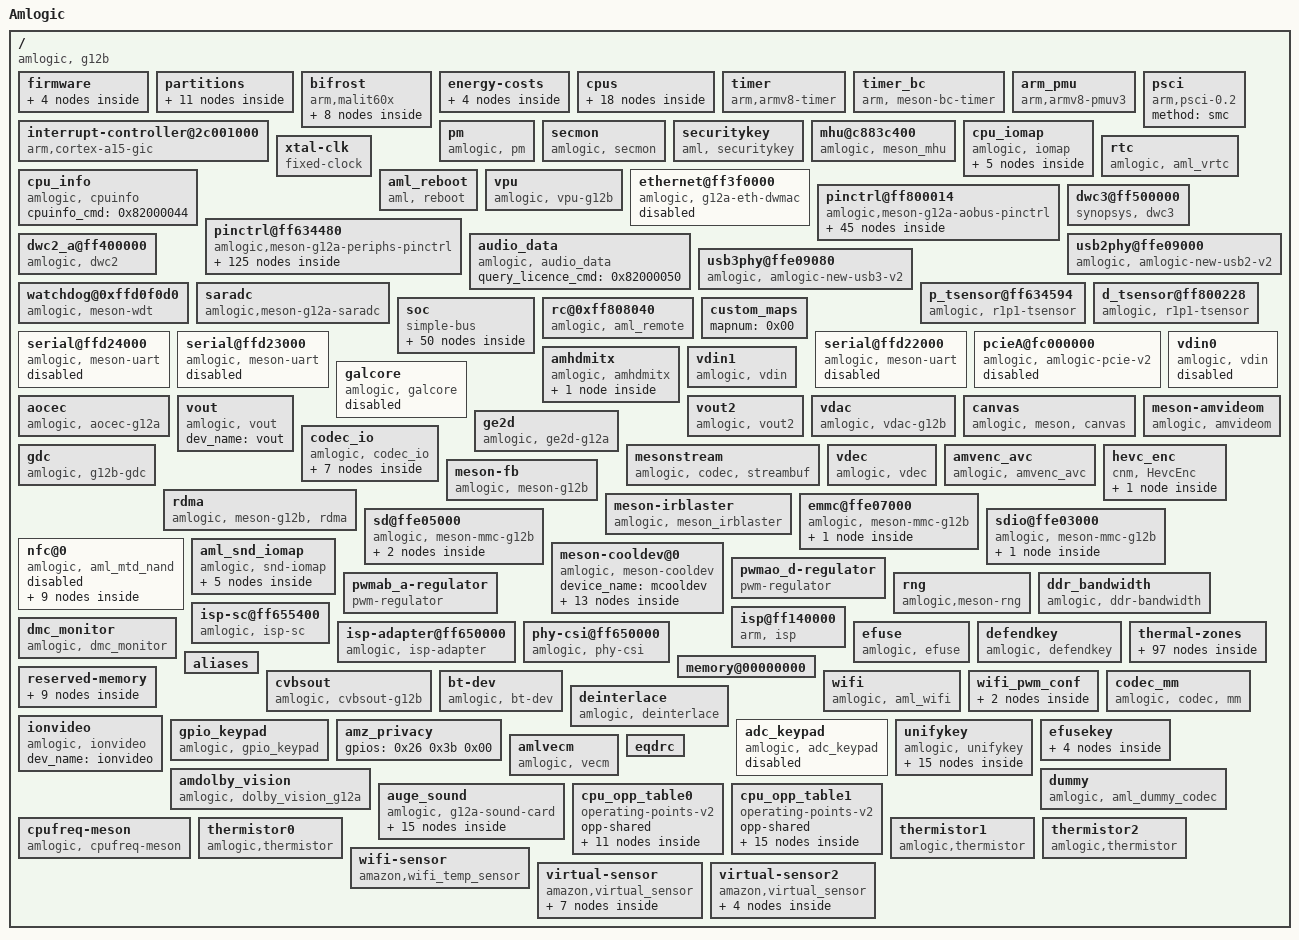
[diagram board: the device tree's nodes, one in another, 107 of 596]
/dts-v1/;

/ {
	model = "Amlogic";
	amlogic-dt-id = "g12brevb_raven_2g";
	compatible = "amlogic, g12b";
	interrupt-parent = <0x01>;
	#address-cells = <0x02>;
	#size-cells = <0x02>;

	firmware {

		android {
			compatible = "android,firmware";

			fstab {
				compatible = "android,fstab";

				vendor {
					compatible = "android,vendor";
					dev = "/dev/block/vendor";
					type = "ext4";
					mnt_flags = "ro";
					fsmgr_flags = "wait,verify";
				};

				odm {
					compatible = "android,odm";
					dev = "/dev/block/odm";
					type = "ext4";
					mnt_flags = "ro,barrier=1,inode_readahead_blks=8";
					fsmgr_flags = "wait";
				};
			};
		};
	};

	partitions {
		parts = <0x0b>;
		part-0 = <0x02>;
		part-1 = <0x03>;
		part-2 = <0x04>;
		part-3 = <0x05>;
		part-4 = <0x06>;
		part-5 = <0x07>;
		part-6 = <0x08>;
		part-7 = <0x09>;
		part-8 = <0x0a>;
		part-9 = <0x0b>;
		part-10 = <0x0c>;
		phandle = <0x99>;

		boot {
			pname = "boot";
			size = <0x00 0x1800000>;
			mask = <0x01>;
			phandle = <0x03>;
		};

		recovery {
			pname = "recovery";
			size = <0x00 0x1800000>;
			mask = <0x01>;
			phandle = <0x04>;
		};

		logo {
			pname = "logo";
			size = <0x00 0x400000>;
			mask = <0x01>;
			phandle = <0x05>;
		};

		tee {
			pname = "tee";
			size = <0x00 0x800000>;
			mask = <0x01>;
			phandle = <0x02>;
		};

		misc {
			pname = "misc";
			size = <0x00 0x100000>;
			mask = <0x02>;
			phandle = <0x06>;
		};

		vendor {
			pname = "vendor";
			size = <0x00 0x9600000>;
			mask = <0x01>;
			phandle = <0x07>;
		};

		odm {
			pname = "odm";
			size = <0x00 0x200000>;
			mask = <0x01>;
			phandle = <0x08>;
		};

		system {
			pname = "system";
			size = <0x00 0x64000000>;
			mask = <0x01>;
			phandle = <0x09>;
		};

		product {
			pname = "product";
			size = <0x00 0x200000>;
			mask = <0x01>;
			phandle = <0x0a>;
		};

		cache {
			pname = "cache";
			size = <0x00 0x20000000>;
			mask = <0x02>;
			phandle = <0x0b>;
		};

		data {
			pname = "data";
			size = <0xffffffff 0xffffffff>;
			mask = <0x04>;
			phandle = <0x0c>;
		};
	};

	bifrost {
		compatible = "arm,malit60x\0arm,malit6xx\0arm,mali-midgard";
		#cooling-cells = <0x02>;
		reg = <0x00 0xffe40000 0x00 0x4000 0x00 0xffd01000 0x00 0x1000 0x00 0xff800000 0x00 0x1000 0x00 0xff63c000 0x00 0x1000 0x00 0xffd01000 0x00 0x1000>;
		interrupt-parent = <0x01>;
		interrupts = <0x00 0xa0 0x04 0x00 0xa1 0x04 0x00 0xa2 0x04>;
		interrupt-names = "GPU\0MMU\0JOB";
		num_of_pp = <0x02>;
		sc_mpp = <0x01>;
		clocks = <0x0d 0x83 0x0d 0x07>;
		clock-names = "gpu_mux\0gp0_pll";
		tbl = <0x0e 0x0f 0x10 0x11 0x12 0x12>;
		system-coherency = <0x00>;
		phandle = <0x9a>;

		clk125_cfg {
			clk_freq = <0x7735940>;
			clk_parent = "fclk_div4";
			clkp_freq = <0x1dcd6500>;
			clk_reg = <0xa03>;
			voltage = <0x47e>;
			keep_count = <0x05>;
			threshold = <0x1e 0x78>;
			phandle = <0x9b>;
		};

		dvfs250_cfg {
			clk_freq = <0xee6b280>;
			clk_parent = "fclk_div4";
			clkp_freq = <0x1dcd6500>;
			clk_reg = <0xa01>;
			voltage = <0x47e>;
			keep_count = <0x05>;
			threshold = <0x50 0xaa>;
			phandle = <0x9c>;
		};

		dvfs285_cfg {
			clk_freq = <0x1107a76d>;
			clk_parent = "fclk_div7";
			clkp_freq = <0x1107a76d>;
			clk_reg = <0xe00>;
			voltage = <0x47e>;
			keep_count = <0x05>;
			threshold = <0x64 0xbe>;
			phandle = <0x0e>;
		};

		dvfs400_cfg {
			clk_freq = <0x17d78400>;
			clk_parent = "fclk_div5";
			clkp_freq = <0x17d78400>;
			clk_reg = <0xc00>;
			voltage = <0x47e>;
			keep_count = <0x05>;
			threshold = <0x98 0xcf>;
			phandle = <0x0f>;
		};

		dvfs500_cfg {
			clk_freq = <0x1dcd6500>;
			clk_parent = "fclk_div4";
			clkp_freq = <0x1dcd6500>;
			clk_reg = <0xa00>;
			voltage = <0x47e>;
			keep_count = <0x05>;
			threshold = <0xb4 0xdc>;
			phandle = <0x10>;
		};

		dvfs666_cfg {
			clk_freq = <0x27bc86aa>;
			clk_parent = "fclk_div3";
			clkp_freq = <0x27bc86aa>;
			clk_reg = <0x800>;
			voltage = <0x47e>;
			keep_count = <0x05>;
			threshold = <0xd2 0xec>;
			phandle = <0x11>;
		};

		dvfs800_cfg {
			clk_freq = <0x2faf0800>;
			clk_parent = "fclk_div2p5";
			clkp_freq = <0x2faf0800>;
			clk_reg = <0x600>;
			voltage = <0x47e>;
			keep_count = <0x05>;
			threshold = <0xe6 0xff>;
			phandle = <0x12>;
		};

		dvfs850_cfg {
			clk_freq = <0x326cef80>;
			clk_parent = "gp0_pll";
			clkp_freq = <0x326cef80>;
			clk_reg = <0x200>;
			voltage = <0x47e>;
			keep_count = <0x05>;
			threshold = <0xe6 0xff>;
			phandle = <0x9d>;
		};
	};

	energy-costs {

		core-cost0 {
			busy-cost-data = <0x36 0x11 0x87 0x6e 0x10e 0xca 0x168 0x108 0x21c 0x18c 0x288 0x1d6 0x2f3 0x22d 0x330 0x26c 0x364 0x2bb 0x398 0x2f7 0x3cc 0x333 0x406 0x377 0x440 0x3a9 0x46e 0x3d0 0x4a8 0x418>;
			idle-cost-data = <0x05 0x00 0x00>;
			phandle = <0x1d>;
		};

		core-cost1 {
			busy-cost-data = <0x21 0x04 0x53 0x17 0xa6 0x29 0xdd 0x36 0x14c 0x4e 0x18f 0x5c 0x1d1 0x74 0x1f7 0x87 0x217 0xa2 0x237 0xb8 0x257 0xe0 0x277 0x117>;
			idle-cost-data = <0x03 0x00 0x00>;
			phandle = <0x19>;
		};

		cluster-cost0 {
			busy-cost-data = <0x36 0x11 0x87 0x14 0x10e 0x19 0x168 0x1b 0x21c 0x23 0x288 0x28 0x2f3 0x31 0x330 0x39 0x364 0x36 0x398 0x40 0x3cc 0x4b 0x406 0x56 0x440 0x61 0x46e 0x6c 0x4a8 0x6e>;
			idle-cost-data = <0x0a 0x0a 0x00>;
			phandle = <0x1e>;
		};

		cluster-cost1 {
			busy-cost-data = <0x21 0x07 0x53 0x08 0xa6 0x09 0xdd 0x0a 0x14c 0x0d 0x18f 0x0f 0x1d1 0x13 0x1f7 0x17 0x217 0x1a 0x237 0x1f 0x257 0x24 0x277 0x2a>;
			idle-cost-data = <0x06 0x06 0x00>;
			phandle = <0x1a>;
		};
	};

	cpus {
		#address-cells = <0x02>;
		#size-cells = <0x00>;
		phandle = <0x9e>;

		cpu-map {

			cluster0 {
				phandle = <0x9f>;

				core0 {
					cpu = <0x13>;
				};

				core1 {
					cpu = <0x14>;
				};
			};

			cluster1 {
				phandle = <0xa0>;

				core0 {
					cpu = <0x15>;
				};

				core1 {
					cpu = <0x16>;
				};

				core2 {
					cpu = <0x17>;
				};

				core3 {
					cpu = <0x18>;
				};
			};
		};

		cpu@0 {
			device_type = "cpu";
			compatible = "arm,cortex-a53\0arm,armv8";
			reg = <0x00 0x00>;
			enable-method = "psci";
			sched-energy-costs = <0x19 0x1a>;
			clocks = <0x0d 0x17 0x0d 0x16 0x0d 0xee>;
			clock-names = "core_clk\0low_freq_clk_parent\0high_freq_clk_parent";
			operating-points-v2 = <0x1b>;
			cpu-supply = <0x1c>;
			voltage-tolerance = <0x00>;
			clock-latency = <0xc350>;
			phandle = <0x13>;
		};

		cpu@1 {
			device_type = "cpu";
			compatible = "arm,cortex-a53\0arm,armv8";
			reg = <0x00 0x01>;
			enable-method = "psci";
			sched-energy-costs = <0x19 0x1a>;
			clocks = <0x0d 0x17 0x0d 0x16 0x0d 0xee>;
			clock-names = "core_clk\0low_freq_clk_parent\0high_freq_clk_parent";
			operating-points-v2 = <0x1b>;
			cpu-supply = <0x1c>;
			voltage-tolerance = <0x00>;
			clock-latency = <0xc350>;
			phandle = <0x14>;
		};

		cpu@100 {
			device_type = "cpu";
			compatible = "arm,cortex-a73\0arm,armv8";
			reg = <0x00 0x100>;
			enable-method = "psci";
			sched-energy-costs = <0x1d 0x1e>;
			clocks = <0x0d 0xde 0x0d 0xdd 0x0d 0x00>;
			clock-names = "core_clk\0low_freq_clk_parent\0high_freq_clk_parent";
			operating-points-v2 = <0x1f>;
			cpu-supply = <0x20>;
			voltage-tolerance = <0x00>;
			clock-latency = <0xc350>;
			phandle = <0x15>;
		};

		cpu@101 {
			device_type = "cpu";
			compatible = "arm,cortex-a73\0arm,armv8";
			reg = <0x00 0x101>;
			enable-method = "psci";
			sched-energy-costs = <0x1d 0x1e>;
			clocks = <0x0d 0xde 0x0d 0xdd 0x0d 0x00>;
			clock-names = "core_clk\0low_freq_clk_parent\0high_freq_clk_parent";
			operating-points-v2 = <0x1f>;
			cpu-supply = <0x20>;
			voltage-tolerance = <0x00>;
			clock-latency = <0xc350>;
			phandle = <0x16>;
		};

		cpu@102 {
			device_type = "cpu";
			compatible = "arm,cortex-a73\0arm,armv8";
			reg = <0x00 0x102>;
			enable-method = "psci";
			sched-energy-costs = <0x1d 0x1e>;
			clocks = <0x0d 0xde 0x0d 0xdd 0x0d 0x00>;
			clock-names = "core_clk\0low_freq_clk_parent\0high_freq_clk_parent";
			operating-points-v2 = <0x1f>;
			cpu-supply = <0x20>;
			voltage-tolerance = <0x00>;
			clock-latency = <0xc350>;
			phandle = <0x17>;
		};

		cpu@103 {
			device_type = "cpu";
			compatible = "arm,cortex-a73\0arm,armv8";
			reg = <0x00 0x103>;
			enable-method = "psci";
			sched-energy-costs = <0x1d 0x1e>;
			clocks = <0x0d 0xde 0x0d 0xdd 0x0d 0x00>;
			clock-names = "core_clk\0low_freq_clk_parent\0high_freq_clk_parent";
			operating-points-v2 = <0x1f>;
			cpu-supply = <0x20>;
			voltage-tolerance = <0x00>;
			clock-latency = <0xc350>;
			phandle = <0x18>;
		};

		idle-states {
			entry-method = "arm,psci";

			cpu-sleep-0 {
				compatible = "arm,idle-state";
				arm,psci-suspend-param = <0x10000>;
				local-timer-stop;
				entry-latency-us = <0x1f40>;
				exit-latency-us = <0x1f40>;
				min-residency-us = <0x4e20>;
				phandle = <0xa1>;
			};

			cluster-sleep-0 {
				compatible = "arm,idle-state";
				arm,psci-suspend-param = <0x1010000>;
				local-timer-stop;
				entry-latency-us = <0x2328>;
				exit-latency-us = <0x2328>;
				min-residency-us = <0x61a8>;
				phandle = <0xa2>;
			};
		};
	};

	timer {
		compatible = "arm,armv8-timer";
		interrupts = <0x01 0x0d 0xff08 0x01 0x0e 0xff08 0x01 0x0b 0xff08 0x01 0x0a 0xff08>;
	};

	timer_bc {
		compatible = "arm, meson-bc-timer";
		reg = <0x00 0xffd0f190 0x00 0x04 0x00 0xffd0f194 0x00 0x04>;
		timer_name = "Meson TimerF";
		clockevent-rating = <0x12c>;
		clockevent-shift = <0x14>;
		clockevent-features = <0x23>;
		interrupts = <0x00 0x3c 0x01>;
		bit_enable = <0x10>;
		bit_mode = <0x0c>;
		bit_resolution = <0x00>;
	};

	arm_pmu {
		compatible = "arm,armv8-pmuv3";
		clusterb-enabled;
		interrupts = <0x00 0x89 0x04 0x00 0xab 0x04>;
		reg = <0x00 0xff634680 0x00 0x04 0x00 0xff6347c0 0x00 0x04>;
		cpumasks = <0x03 0x3c>;
		relax-timer-ns = <0x989680>;
		max-wait-cnt = <0x2710>;
	};

	interrupt-controller@2c001000 {
		compatible = "arm,cortex-a15-gic\0arm,cortex-a9-gic";
		#interrupt-cells = <0x03>;
		#address-cells = <0x00>;
		interrupt-controller;
		reg = <0x00 0xffc01000 0x00 0x1000 0x00 0xffc02000 0x00 0x100>;
		interrupts = <0x01 0x09 0xf04>;
		phandle = <0x01>;
	};

	psci {
		compatible = "arm,psci-0.2";
		method = "smc";
	};

	pm {
		compatible = "amlogic, pm";
		status = "okay";
		device_name = "aml_pm";
		reg = <0x00 0xff8000a8 0x00 0x04 0x00 0xff80023c 0x00 0x04>;
		phandle = <0xa3>;
	};

	secmon {
		compatible = "amlogic, secmon";
		memory-region = <0x21>;
		in_base_func = <0x82000020>;
		out_base_func = <0x82000021>;
		reserve_mem_size = <0x2300000>;
		clear_range = <0x5100000 0x1e00000>;
	};

	securitykey {
		compatible = "aml, securitykey";
		storage_query = <0x82000060>;
		storage_read = <0x82000061>;
		storage_write = <0x82000062>;
		storage_tell = <0x82000063>;
		storage_verify = <0x82000064>;
		storage_status = <0x82000065>;
		storage_list = <0x82000067>;
		storage_remove = <0x82000068>;
		storage_in_func = <0x82000023>;
		storage_out_func = <0x82000024>;
		storage_block_func = <0x82000025>;
		storage_size_func = <0x82000027>;
		storage_set_enctype = <0x8200006a>;
		storage_get_enctype = <0x8200006b>;
		storage_version = <0x8200006c>;
	};

	mhu@c883c400 {
		compatible = "amlogic, meson_mhu";
		reg = <0x00 0xff63c400 0x00 0x4c 0x00 0xfffe7000 0x00 0x800>;
		interrupts = <0x00 0xd1 0x01 0x00 0xd2 0x01>;
		#mbox-cells = <0x01>;
		mbox-names = "cpu_to_scp_low\0cpu_to_scp_high";
		mboxes = <0x22 0x00 0x22 0x01>;
		phandle = <0x22>;
	};

	cpu_iomap {
		compatible = "amlogic, iomap";
		#address-cells = <0x02>;
		#size-cells = <0x02>;
		ranges;

		io_cbus_base {
			reg = <0x00 0xffd00000 0x00 0x26000>;
		};

		io_apb_base {
			reg = <0x00 0xffe01000 0x00 0x7f000>;
		};

		io_aobus_base {
			reg = <0x00 0xff800000 0x00 0xb000>;
		};

		io_vapb_base {
			reg = <0x00 0xff900000 0x00 0x50000>;
		};

		io_hiu_base {
			reg = <0x00 0xff63c000 0x00 0x2000>;
		};
	};

	xtal-clk {
		compatible = "fixed-clock";
		clock-frequency = <0x16e3600>;
		clock-output-names = "xtal";
		#clock-cells = <0x00>;
		phandle = <0x27>;
	};

	rtc {
		compatible = "amlogic, aml_vrtc";
		alarm_reg_addr = <0xff8000a8>;
		timer_e_addr = <0xffd0f188>;
		init_date = "2019/01/01";
		status = "okay";
	};

	cpu_info {
		compatible = "amlogic, cpuinfo";
		status = "okay";
		cpuinfo_cmd = <0x82000044>;
	};

	aml_reboot {
		compatible = "aml, reboot";
		sys_reset = <0x84000009>;
		sys_poweroff = <0x84000008>;
	};

	vpu {
		compatible = "amlogic, vpu-g12b";
		dev_name = "vpu";
		status = "okay";
		clocks = <0x0d 0x95 0x0d 0x4c 0x0d 0x87 0x0d 0x8b 0x0d 0x8c>;
		clock-names = "vapb_clk\0vpu_intr_gate\0vpu_clk0\0vpu_clk1\0vpu_clk";
		clk_level = <0x07>;
	};

	ethernet@ff3f0000 {
		compatible = "amlogic, g12a-eth-dwmac\0snps,dwmac";
		reg = <0x00 0xff3f0000 0x00 0x10000 0x00 0xff634540 0x00 0x08 0x00 0xff64c000 0x00 0xa0>;
		reg-names = "eth_base\0eth_cfg\0eth_pll";
		interrupts = <0x00 0x08 0x01>;
		interrupt-names = "macirq";
		status = "disable";
		clocks = <0x0d 0x38>;
		clock-names = "ethclk81";
		pll_val = <0x9c0040a 0x927e0000 0xac5f49e5>;
		analog_val = <0x20200000 0xc000 0x23>;
		pinctrl-names = "external_eth_pins";
		pinctrl-0 = <0x23>;
		mc_val = <0x1621>;
		internal_phy = <0x00>;
		phandle = <0xa4>;
	};

	pinctrl@ff800014 {
		compatible = "amlogic,meson-g12a-aobus-pinctrl";
		#address-cells = <0x02>;
		#size-cells = <0x02>;
		ranges;
		phandle = <0xa5>;

		ao-bank@ff800014 {
			reg = <0x00 0xff800014 0x00 0x08 0x00 0xff800024 0x00 0x14 0x00 0xff80001c 0x00 0x08>;
			reg-names = "mux\0gpio\0drive-strength";
			gpio-controller;
			#gpio-cells = <0x02>;
			phandle = <0xa6>;
		};

		ao_uart {
			phandle = <0xa7>;

			mux {
				groups = "uart_ao_tx_a\0uart_ao_rx_a";
				function = "uart_ao_a";
			};
		};

		ao_b_uart {
			phandle = <0x2c>;

			mux {
				groups = "uart_ao_tx_b_2\0uart_ao_rx_b_3";
				function = "uart_ao_b";
			};
		};

		ao_i2c_pins1 {
			phandle = <0x2a>;

			mux {
				groups = "i2c_ao_sck\0i2c_ao_sda";
				function = "i2c_ao";
				bias-pull-up;
				drive-strength = <0x02>;
			};
		};

		ao_i2c_pins2 {
			phandle = <0xa8>;

			mux {
				groups = "i2c_ao_sck_e\0i2c_ao_sda_e";
				function = "i2c_ao";
				bias-pull-up;
				drive-strength = <0x02>;
			};
		};

		ao_i2c_slave_pins {
			phandle = <0x2b>;

			mux {
				groups = "i2c_ao_slave_sck\0i2c_ao_slave_sda";
				function = "i2c_ao_slave";
			};
		};

		pwm_ao_a {
			phandle = <0xa9>;

			mux {
				groups = "pwm_ao_a";
				function = "pwm_ao_a";
			};
		};

		pwm_ao_a_hiz {
			phandle = <0xaa>;

			mux {
				groups = "pwm_ao_a_hiz";
				function = "pwm_ao_a";
			};
		};

		pwm_ao_b {
			phandle = <0xab>;

			mux {
				groups = "pwm_ao_b";
				function = "pwm_ao_b";
			};
		};

		pwm_ao_c_pins1 {
			phandle = <0xac>;

			mux {
				groups = "pwm_ao_c_4";
				function = "pwm_ao_c";
			};
		};

		pwm_ao_c_pins2 {
			phandle = <0xad>;

			mux {
				groups = "pwm_ao_c_6";
				function = "pwm_ao_c";
			};
		};

		pwm_ao_c_hiz {
			phandle = <0xae>;

			mux {
				groups = "pwm_ao_c_hiz_4";
				function = "pwm_ao_c";
			};
		};

		pwm_ao_d_pins1 {
			phandle = <0xaf>;

			mux {
				groups = "pwm_ao_d_5";
				function = "pwm_ao_d";
			};
		};

		pwm_ao_d_pins2 {
			phandle = <0xb0>;

			mux {
				groups = "pwm_ao_d_10";
				function = "pwm_ao_d";
			};
		};

		pwm_ao_d_pins3 {
			phandle = <0x56>;

			mux {
				groups = "pwm_ao_d_e";
				function = "pwm_ao_d";
			};
		};

		ao_ceca {
			phandle = <0xb1>;

			mux {
				groups = "cec_ao_a";
				function = "cec_ao";
			};
		};

		ao_cecb {
			phandle = <0xb2>;

			mux {
				groups = "cec_ao_b";
				function = "cec_ao";
			};
		};

		pwm_a_e2 {
			phandle = <0x58>;

			mux {
				groups = "pwm_a_e2";
				function = "pwm_a_gpioe";
			};
		};

		sd_to_ao_uart_clr_pins {
			phandle = <0x4c>;

			mux {
				groups = "GPIOAO_0\0GPIOAO_1";
				function = "gpio_aobus";
			};
		};

		sd_to_ao_uart_pins {
			phandle = <0x4e>;

			mux {
				groups = "uart_ao_tx_a\0uart_ao_rx_a";
				function = "uart_ao_a";
				bias-pull-up;
				input-enable;
			};
		};

		remote_pin {
			phandle = <0x36>;

			mux {
				groups = "remote_input_ao";
				function = "remote_input_ao";
			};
		};

		irblaster_pin {
			phandle = <0x44>;

			mux {
				groups = "remote_out_ao";
				function = "remote_out_ao";
			};
		};

		irblaster_pin1 {
			phandle = <0xb3>;

			mux {
				groups = "remote_out_ao9";
				function = "remote_out_ao";
			};
		};
	};

	pinctrl@ff634480 {
		compatible = "amlogic,meson-g12a-periphs-pinctrl";
		#address-cells = <0x02>;
		#size-cells = <0x02>;
		ranges;
		phandle = <0xb4>;

		banks@ff6346c0 {
			reg = <0x00 0xff6346c0 0x00 0x40 0x00 0xff6344e8 0x00 0x18 0x00 0xff634520 0x00 0x18 0x00 0xff634440 0x00 0x4c 0x00 0xff634740 0x00 0x1c>;
			reg-names = "mux\0pull\0pull-enable\0gpio\0drive-strength";
			gpio-controller;
			#gpio-cells = <0x02>;
			phandle = <0x26>;
		};

		emmc_clk_cmd_pins {
			phandle = <0x46>;

			mux {
				groups = "emmc_clk\0emmc_cmd";
				function = "emmc";
				input-enable;
				bias-pull-up;
				drive-strength = <0x03>;
			};
		};

		emmc_conf_pull_up {
			phandle = <0x47>;

			mux {
				groups = "emmc_nand_d7\0emmc_nand_d6\0emmc_nand_d5\0emmc_nand_d4\0emmc_nand_d3\0emmc_nand_d2\0emmc_nand_d1\0emmc_nand_d0\0emmc_clk\0emmc_cmd";
				function = "emmc";
				input-enable;
				bias-pull-up;
				drive-strength = <0x03>;
			};
		};

		emmc_conf_pull_done {
			phandle = <0x48>;

			mux {
				groups = "emmc_nand_ds";
				function = "emmc";
				input-enable;
				bias-pull-down;
				drive-strength = <0x03>;
			};
		};

		sd_clk_cmd_pins {
			phandle = <0x4a>;

			mux {
				groups = "sdcard_cmd_c\0sdcard_clk_c";
				function = "sdcard";
				input-enable;
				bias-pull-up;
				drive-strength = <0x03>;
			};
		};

		sd_all_pins {
			phandle = <0x49>;

			mux {
				groups = "sdcard_d0_c\0sdcard_d1_c\0sdcard_d2_c\0sdcard_d3_c\0sdcard_cmd_c\0sdcard_clk_c";
				function = "sdcard";
				input-enable;
				bias-pull-up;
				drive-strength = <0x03>;
			};
		};

		sd_1bit_pins {
			phandle = <0x4b>;

			mux {
				groups = "sdcard_d0_c\0sdcard_cmd_c\0sdcard_clk_c";
				function = "sdcard";
				input-enable;
				bias-pull-up;
				drive-strength = <0x03>;
			};
		};

		ao_to_sd_uart_pins {
			phandle = <0x4d>;

			mux {
				groups = "uart_ao_tx_a_c3\0uart_ao_rx_a_c2";
				function = "uart_ao_a_ee";
				bias-pull-up;
				input-enable;
			};
		};

		sdio_clk_cmd_pins {
			phandle = <0x50>;

			mux {
				groups = "sdio_clk\0sdio_cmd";
				function = "sdio";
				input-enable;
				bias-pull-up;
				drive-strength = <0x03>;
			};
		};

		sdio_all_pins {
			phandle = <0x4f>;

			mux {
				groups = "sdio_d0\0sdio_d1\0sdio_d2\0sdio_d3\0sdio_clk\0sdio_cmd";
				function = "sdio";
				input-enable;
				bias-pull-up;
				drive-strength = <0x03>;
			};
		};

		all_nand_pins {
			phandle = <0x51>;

			mux {
				groups = "emmc_nand_d0\0emmc_nand_d1\0emmc_nand_d2\0emmc_nand_d3\0emmc_nand_d4\0emmc_nand_d5\0emmc_nand_d6\0emmc_nand_d7\0nand_ce0\0nand_ale\0nand_cle\0nand_wen_clk\0nand_ren_wr\0nand_rb0";
				function = "nand";
				input-enable;
			};
		};

		nand_cs {
			phandle = <0x52>;

			mux {
				groups = "nand_ce0";
				function = "nand";
			};
		};

		i2c0_pins1 {
			phandle = <0xb5>;

			mux {
				groups = "i2c0_sda_c\0i2c0_sck_c";
				function = "i2c0";
				bias-pull-up;
				drive-strength = <0x02>;
			};
		};

		i2c0_pins2 {
			phandle = <0x28>;

			mux {
				groups = "i2c0_sda_z0\0i2c0_sck_z1";
				function = "i2c0";
				bias-pull-up;
				drive-strength = <0x02>;
			};
		};

		i2c0_pins3 {
			phandle = <0xb6>;

			mux {
				groups = "i2c0_sda_z7\0i2c0_sck_z8";
				function = "i2c0";
				bias-pull-up;
				drive-strength = <0x02>;
			};
		};

		i2c1_pins1 {
			phandle = <0xb7>;

			mux {
				groups = "i2c1_sda_x\0i2c1_sck_x";
				function = "i2c1";
				bias-pull-up;
				drive-strength = <0x02>;
			};
		};

		i2c1_pins2 {
			phandle = <0xb8>;

			mux {
				groups = "i2c1_sda_h2\0i2c1_sck_h3";
				function = "i2c1";
				bias-pull-up;
				drive-strength = <0x02>;
			};
		};

		i2c1_pins3 {
			phandle = <0xb9>;

			mux {
				groups = "i2c1_sda_h6\0i2c1_sck_h7";
				function = "i2c1";
				bias-pull-up;
				drive-strength = <0x02>;
			};
		};

		i2c2_pins1 {
			phandle = <0xba>;

			mux {
				groups = "i2c2_sda_x\0i2c2_sck_x";
				function = "i2c2";
				bias-pull-up;
				drive-strength = <0x02>;
			};
		};

		i2c2_pins2 {
			phandle = <0xbb>;

			mux {
				groups = "i2c2_sda_z\0i2c2_sck_z";
				function = "i2c2";
				bias-pull-up;
				drive-strength = <0x02>;
			};
		};

		i2c3_pins1 {
			phandle = <0x3f>;

			mux {
				groups = "i2c3_sda_h\0i2c3_sck_h";
				function = "i2c3";
				bias-pull-up;
				drive-strength = <0x02>;
			};
		};

		i2c3_pins2 {
			phandle = <0x29>;

			mux {
				groups = "i2c3_sda_a\0i2c3_sck_a";
				function = "i2c3";
				bias-pull-up;
				drive-strength = <0x02>;
			};
		};

		pwm_a {
			phandle = <0xbc>;

			mux {
				groups = "pwm_a";
				function = "pwm_a";
			};
		};

		pwm_b_pins1 {
			phandle = <0xbd>;

			mux {
				groups = "pwm_b_x7";
				function = "pwm_b";
			};
		};

		pwm_b_pins2 {
			phandle = <0xbe>;

			mux {
				groups = "pwm_b_x19";
				function = "pwm_b";
			};
		};

		pwm_b_pins3 {
			phandle = <0xbf>;

			mux {
				groups = "pwm_b_h";
				function = "pwm_b";
			};
		};

		pwm_b_pins4 {
			phandle = <0xc0>;

			mux {
				groups = "pwm_b_z0";
				function = "pwm_b";
			};
		};

		pwm_b_pins5 {
			phandle = <0xc1>;

			mux {
				groups = "pwm_b_z13";
				function = "pwm_b";
			};
		};

		pwm_c_pins1 {
			phandle = <0xc2>;

			mux {
				groups = "pwm_c_c4";
				function = "pwm_c";
			};
		};

		pwm_c_pins2 {
			phandle = <0xc3>;

			mux {
				groups = "pwm_c_x5";
				function = "pwm_c";
			};
		};

		pwm_c_pins3 {
			phandle = <0xc4>;

			mux {
				groups = "pwm_c_x8";
				function = "pwm_c";
			};
		};

		pwm_c_pins4 {
			phandle = <0xc5>;

			mux {
				groups = "pwm_c_z";
				function = "pwm_c";
			};
		};

		pwm_d_pins1 {
			phandle = <0xc6>;

			mux {
				groups = "pwm_d_x3";
				function = "pwm_d";
			};
		};

		pwm_d_pins2 {
			phandle = <0xc7>;

			mux {
				groups = "pwm_d_x6";
				function = "pwm_d";
			};
		};

		pwm_d_pins3 {
			phandle = <0xc8>;

			mux {
				groups = "pwm_d_z";
				function = "pwm_d";
			};
		};

		pwm_d_pins4 {
			phandle = <0xc9>;

			mux {
				groups = "pwm_d_a4";
				function = "pwm_d";
			};
		};

		pwm_e {
			phandle = <0xca>;

			mux {
				groups = "pwm_e";
				function = "pwm_e";
			};
		};

		pwm_f_pins1 {
			phandle = <0xcb>;

			mux {
				groups = "pwm_f_x";
				function = "pwm_f";
			};
		};

		pwm_f_pins2 {
			phandle = <0xcc>;

			mux {
				groups = "pwm_f_h";
				function = "pwm_f";
			};
		};

		pwm_f_pins3 {
			phandle = <0xcd>;

			mux {
				groups = "pwm_f_z";
				function = "pwm_f";
			};
		};

		pwm_f_pins4 {
			phandle = <0xce>;

			mux {
				groups = "pwm_f_a11";
				function = "pwm_f";
			};
		};

		spicc0_pins_x {
			phandle = <0xcf>;

			mux {
				groups = "spi0_mosi_x\0spi0_miso_x\0spi0_clk_x";
				function = "spi0";
				drive-strength = <0x01>;
			};
		};

		spicc1_pins {
			phandle = <0xd0>;

			mux {
				groups = "spi1_mosi\0spi1_miso\0spi1_clk";
				function = "spi1";
				drive-strength = <0x01>;
			};
		};

		a_uart {
			phandle = <0x38>;

			mux {
				groups = "uart_tx_a\0uart_rx_a\0uart_cts_a\0uart_rts_a";
				function = "uart_a";
			};
		};

		b_uart {
			phandle = <0x39>;

			mux {
				groups = "uart_tx_b\0uart_rx_b";
				function = "uart_b";
			};
		};

		c_uart {
			phandle = <0x3a>;

			mux {
				groups = "uart_tx_c\0uart_rx_c";
				function = "uart_c";
			};
		};

		hdmitx_hpd {
			phandle = <0x3c>;

			mux {
				groups = "hdmitx_hpd_in";
				function = "hdmitx";
				bias-disable;
			};
		};

		hdmitx_hpd_gpio {
			phandle = <0x3e>;

			mux {
				groups = "GPIOH_1";
				function = "gpio_periphs";
				bias-disable;
			};
		};

		hdmitx_ddc {
			phandle = <0x3d>;

			mux {
				groups = "hdmitx_sda\0hdmitx_sck";
				function = "hdmitx";
				bias-disable;
			};
		};

		ee_ceca {
			phandle = <0x40>;

			mux {
				groups = "cec_ao_a_ee";
				function = "cec_ao_ee";
			};
		};

		ee_cecb {
			phandle = <0x41>;

			mux {
				groups = "cec_ao_b_ee";
				function = "cec_ao_ee";
			};
		};

		internal_eth_pins {
			phandle = <0xd1>;

			mux {
				groups = "eth_link_led\0eth_act_led";
				function = "eth";
			};
		};

		external_eth_pins {
			phandle = <0x23>;

			mux {
				groups = "eth_mdio\0eth_mdc\0eth_rgmii_rx_clk\0eth_rx_dv\0eth_rxd0\0eth_rxd1\0eth_rxd2_rgmii\0eth_rxd3_rgmii\0eth_rgmii_tx_clk\0eth_txen\0eth_txd0\0eth_txd1\0eth_txd2_rgmii\0eth_txd3_rgmii";
				function = "eth";
				drive-strength = <0x03>;
			};
		};

		irblaster_pins2 {
			phandle = <0xd2>;

			mux {
				groups = "remote_out_h";
				function = "remote_out";
			};
		};

		irblaster_pins3 {
			phandle = <0xd3>;

			mux {
				groups = "remote_out_z";
				function = "remote_out";
			};
		};

		tdmout_a {
			phandle = <0x2f>;

			mux {
				groups = "tdma_sclk\0tdma_fs\0tdma_dout0";
				function = "tdma_out";
			};
		};

		tdmin_a {
			phandle = <0x30>;

			mux {
				groups = "tdma_din1";
				function = "tdma_in";
			};
		};

		tdmb_mclk {
			phandle = <0x31>;

			mux {
				groups = "mclk0_a";
				function = "mclk0";
				drive-strength = <0x02>;
			};
		};

		tdmout_b {
			phandle = <0x32>;

			mux {
				groups = "tdmb_sclk\0tdmb_fs\0tdmb_dout0";
				function = "tdmb_out";
				drive-strength = <0x02>;
			};
		};

		tdmc_mclk {
			phandle = <0xd4>;

			mux {
				groups = "mclk1_a";
				function = "mclk1";
			};
		};

		tdmout_c {
			phandle = <0x33>;

			mux {
				groups = "tdmc_sclk_a\0tdmc_fs_a";
				function = "tdmc_out";
				drive-strength = <0x03>;
			};
		};

		tdmin_c {
			phandle = <0x34>;

			mux {
				groups = "tdmc_din0_a";
				function = "tdmc_in";
				drive-strength = <0x03>;
			};
		};

		spdifin {
			phandle = <0x35>;

			mux {
				groups = "spdif_in_h";
				function = "spdif_in";
			};
		};
	};

	audio_data {
		compatible = "amlogic, audio_data";
		query_licence_cmd = <0x82000050>;
		status = "okay";
		phandle = <0xd5>;
	};

	dwc3@ff500000 {
		compatible = "synopsys, dwc3";
		status = "okay";
		reg = <0x00 0xff500000 0x00 0x100000>;
		interrupts = <0x00 0x1e 0x04>;
		usb-phy = <0x24 0x25>;
		cpu-type = "gxl";
		clock-src = "usb3.0";
		clocks = <0x0d 0x41>;
		clock-names = "dwc_general";
		phandle = <0xd6>;
	};

	usb2phy@ffe09000 {
		compatible = "amlogic, amlogic-new-usb2-v2";
		status = "okay";
		reg = <0x00 0xffe09000 0x00 0x80 0x00 0xffd01008 0x00 0x100 0x00 0xff636000 0x00 0x2000 0x00 0xff63a000 0x00 0x2000>;
		pll-setting-1 = <0x9400414>;
		pll-setting-2 = <0x927e0000>;
		pll-setting-3 = <0xac5f69e5>;
		pll-setting-4 = <0xfe18>;
		pll-setting-5 = <0x8000fff>;
		pll-setting-6 = <0x78000>;
		pll-setting-7 = <0xe0004>;
		pll-setting-8 = <0xe000c>;
		portnum = <0x02>;
		phandle = <0x24>;
	};

	usb3phy@ffe09080 {
		compatible = "amlogic, amlogic-new-usb3-v2";
		status = "okay";
		reg = <0x00 0xffe09080 0x00 0x20>;
		phy-reg = <0xff646000>;
		phy-reg-size = <0x2000>;
		usb2-phy-reg = <0xffe09000>;
		usb2-phy-reg-size = <0x80>;
		interrupts = <0x00 0x10 0x04>;
		clocks = <0x0d 0x18>;
		clock-names = "pcie_refpll";
		portnum = <0x01>;
		otg = <0x00>;
		gpio-vbus-power = "GPIOH_4";
		gpios = <0x26 0x15 0x00>;
		phandle = <0x25>;
	};

	dwc2_a@ff400000 {
		compatible = "amlogic, dwc2";
		status = "okay";
		device_name = "dwc2_a";
		reg = <0x00 0xff400000 0x00 0x40000>;
		interrupts = <0x00 0x1f 0x04>;
		pl-periph-id = <0x00>;
		clock-src = "usb0";
		port-id = <0x00>;
		port-type = <0x02>;
		port-speed = <0x00>;
		port-config = <0x00>;
		port-dma = <0x00>;
		port-id-mode = <0x00>;
		usb-fifo = <0x2d8>;
		cpu-type = "v2";
		phy-reg = <0xffe09000>;
		phy-reg-size = <0xa0>;
		phy-interface = <0x00>;
		clocks = <0x0d 0x41 0x0d 0x49>;
		clock-names = "usb_general\0usb1";
		controller-type = <0x04>;
		phandle = <0xd7>;
	};

	watchdog@0xffd0f0d0 {
		compatible = "amlogic, meson-wdt";
		status = "okay";
		default_timeout = <0x0a>;
		reset_watchdog_method = <0x01>;
		reset_watchdog_time = <0x02>;
		shutdown_timeout = <0x0a>;
		firmware_timeout = <0x06>;
		suspend_timeout = <0x06>;
		reg = <0x00 0xffd0f0d0 0x00 0x10>;
		clock-names = "xtal";
		clocks = <0x27>;
		phandle = <0xd8>;
	};

	saradc {
		compatible = "amlogic,meson-g12a-saradc";
		status = "okay";
		#io-channel-cells = <0x01>;
		clocks = <0x27 0x0d 0x103>;
		clock-names = "xtal\0saradc_clk";
		interrupts = <0x00 0xc8 0x01>;
		reg = <0x00 0xff809000 0x00 0x48>;
		phandle = <0x45>;
	};

	p_tsensor@ff634594 {
		compatible = "amlogic, r1p1-tsensor";
		device_name = "meson-pthermal";
		status = "okay";
		reg = <0x00 0xff634800 0x00 0x50 0x00 0xff800268 0x00 0x04>;
		cal_type = <0x01>;
		cal_a = <0x144>;
		cal_b = <0x1a8>;
		cal_c = <0xc57>;
		cal_d = <0x24c3>;
		rtemp = <0x1c138>;
		interrupts = <0x00 0x23 0x00>;
		clocks = <0x0d 0xd6>;
		clock-names = "ts_comp";
		#thermal-sensor-cells = <0x01>;
		phandle = <0x5d>;
	};

	d_tsensor@ff800228 {
		compatible = "amlogic, r1p1-tsensor";
		device_name = "meson-dthermal";
		status = "okay";
		reg = <0x00 0xff634c00 0x00 0x50 0x00 0xff800230 0x00 0x04>;
		cal_type = <0x01>;
		cal_a = <0x144>;
		cal_b = <0x1a8>;
		cal_c = <0xc57>;
		cal_d = <0x24c3>;
		rtemp = <0x1c138>;
		interrupts = <0x00 0x24 0x00>;
		clocks = <0x0d 0xd6>;
		clock-names = "ts_comp";
		#thermal-sensor-cells = <0x01>;
		phandle = <0x67>;
	};

	soc {
		compatible = "simple-bus";
		#address-cells = <0x02>;
		#size-cells = <0x02>;
		ranges;

		cbus@ffd00000 {
			compatible = "simple-bus";
			reg = <0x00 0xffd00000 0x00 0x26000>;
			#address-cells = <0x02>;
			#size-cells = <0x02>;
			ranges = <0x00 0x00 0x00 0xffd00000 0x00 0x26000>;
			phandle = <0xd9>;

			interrupt-controller@f080 {
				compatible = "amlogic,meson-gpio-intc-ext\0amlogic,meson-g12a-gpio-intc";
				reg = <0x00 0xf080 0x00 0x10>;
				interrupt-controller;
				#interrupt-cells = <0x02>;
				amlogic,channel-interrupts = <0x40 0x41 0x42 0x43 0x44 0x45 0x46 0x47>;
				status = "okay";
				phandle = <0xda>;
			};

			meson_clk_msr {
				compatible = "amlogic, gxl_measure";
				reg = <0x00 0x18004 0x00 0x04 0x00 0x1800c 0x00 0x04>;
			};

			pwm@1b000 {
				compatible = "amlogic,g12b-ee-pwm";
				reg = <0x00 0x1b000 0x00 0x20>;
				#pwm-cells = <0x03>;
				clocks = <0x27 0x27 0x27 0x27>;
				clock-names = "clkin0\0clkin1\0clkin2\0clkin3";
				status = "okay";
				phandle = <0x59>;
			};

			pwm@1a000 {
				compatible = "amlogic,g12b-ee-pwm";
				reg = <0x00 0x1a000 0x00 0x20>;
				#pwm-cells = <0x03>;
				clocks = <0x27 0x27 0x27 0x27>;
				clock-names = "clkin0\0clkin1\0clkin2\0clkin3";
				status = "disabled";
				phandle = <0xdb>;
			};

			pwm@19000 {
				compatible = "amlogic,g12b-ee-pwm";
				reg = <0x00 0x19000 0x00 0x20>;
				#pwm-cells = <0x03>;
				clocks = <0x27 0x27 0x27 0x27>;
				clock-names = "clkin0\0clkin1\0clkin2\0clkin3";
				status = "okay";
				phandle = <0x75>;
			};

			i2c@1f000 {
				compatible = "amlogic,meson-g12b-i2c";
				status = "disabled";
				reg = <0x00 0x1f000 0x00 0x20>;
				interrupts = <0x00 0x15 0x01 0x00 0x5b 0x01>;
				#address-cells = <0x01>;
				#size-cells = <0x00>;
				clocks = <0x0d 0x2a>;
				clock-names = "clk_i2c";
				pinctrl-names = "default";
				pinctrl-0 = <0x28>;
				clock-frequency = <0x61a80>;
				phandle = <0xdc>;

				touchscreen@5d {
					compatible = "goodix,gt9xx";
					status = "disabled";
					reg = <0x5d>;
					reset-gpio = <0x26 0x0a 0x00>;
					irq-gpio = <0x26 0x04 0x00>;
					goodix,cfg-group0 = [41 00 04 58 02 05 0c 00 02 54 07 0f 50 2d 03 05 00 00 00 00 40 00 04 20 10 f3 aa 07 28 0a 2c 2e 7c 06 00 00 00 c9 03 24 00 01 00 00 00 00 ff 5d 66 98 32 28 64 94 c5 02 08 00 00 01 91 2c 00 8a 34 00 8a 3f 00 7e 4c 00 78 5b 00 78 00 00 00 00 00 00 00 00 00 00 00 00 00 00 00 00 00 00 00 00 00 00 00 00 00 00 00 00 00 00 00 00 00 00 00 00 02 04 06 08 0a 0c 0e 10 12 14 ff ff ff ff 00 00 00 00 00 00 00 00 00 00 00 00 00 00 00 00 00 02 04 06 08 0a 0c 1d 1e 1f 20 21 22 24 26 ff ff ff ff ff ff ff ff ff ff ff 00 00 00 00 00 00 00 00 00 00 00 00 00 00 00 00 e3 01];
				};

				touchscreen@38 {
					compatible = "focaltech,fts";
					status = "disabled";
					reg = <0x38>;
					reset-gpio = <0x26 0x0a 0x00>;
					irq-gpio = <0x26 0x04 0x00>;
					x_max = <0x2d0>;
					y_max = <0x500>;
					max-touch-number = <0x0a>;
				};
			};

			i2c@1e000 {
				compatible = "amlogic,meson-g12b-i2c";
				status = "disabled";
				reg = <0x00 0x1e000 0x00 0x20>;
				interrupts = <0x00 0xd6 0x01 0x00 0x5c 0x01>;
				#address-cells = <0x01>;
				#size-cells = <0x00>;
				clocks = <0x0d 0x2a>;
				clock-names = "clk_i2c";
				phandle = <0xdd>;
			};

			i2c@1d000 {
				compatible = "amlogic,meson-g12b-i2c";
				status = "disabled";
				reg = <0x00 0x1d000 0x00 0x20>;
				interrupts = <0x00 0xd7 0x01 0x00 0x5e 0x01>;
				#address-cells = <0x01>;
				#size-cells = <0x00>;
				clocks = <0x0d 0x2a>;
				clock-names = "clk_i2c";
				phandle = <0xde>;
			};

			i2c@1c000 {
				compatible = "amlogic,meson-g12b-i2c";
				status = "okay";
				reg = <0x00 0x1c000 0x00 0x20>;
				interrupts = <0x00 0x27 0x01 0x00 0x5f 0x01>;
				#address-cells = <0x01>;
				#size-cells = <0x00>;
				clocks = <0x0d 0x2a>;
				clock-names = "clk_i2c";
				pinctrl-names = "default";
				pinctrl-0 = <0x29>;
				clock-frequency = <0x61a80>;
				phandle = <0xdf>;

				is31fl3236@3F {
					compatible = "issi,is31fl3236";
					reg = <0x3f>;
					play-boot-animation;
					enable-gpio = <0x26 0x36 0x00>;
					buck-gpio = <0x26 0x28 0x00>;
					channel-offset = [0c];
					setup-device;
				};

				tlv320adc3101_30@30 {
					compatible = "ti,tlv320adc3101";
					#sound-dai-cells = <0x00>;
					reg = <0x18>;
					gpio-reset = <0x26 0x37 0x00>;
					slot_number = <0x00>;
					differential_pair = <0x01>;
					status = "okay";
					phandle = <0x93>;
				};

				tlv320adc3101_32@32 {
					compatible = "ti,tlv320adc3101";
					#sound-dai-cells = <0x00>;
					reg = <0x19>;
					slot_number = <0x01>;
					differential_pair = <0x01>;
					status = "okay";
					phandle = <0x94>;
				};

				tlv320adc3101_34@34 {
					compatible = "ti,tlv320adc3101";
					#sound-dai-cells = <0x00>;
					reg = <0x1a>;
					slot_number = <0x02>;
					differential_pair = <0x01>;
					status = "okay";
					phandle = <0x95>;
				};

				tlv320adc3101_36@36 {
					compatible = "ti,tlv320adc3101";
					#sound-dai-cells = <0x00>;
					reg = <0x1b>;
					slot_number = <0x03>;
					differential_pair = <0x01>;
					status = "okay";
					phandle = <0x96>;
				};

				tlv320adc3101_00@00 {
					compatible = "ti,tlv320adc3101";
					#sound-dai-cells = <0x00>;
					reg = <0x00>;
					slot_number = <0x04>;
					status = "okay";
					phandle = <0xe0>;
				};

				tsl2540@39 {
					compatible = "amstaos,tsl2540";
					reg = <0x39>;
					als_name = "taos_als";
					persist = <0x12>;
					als_gain = <0x03>;
					als_gain_factor = <0x01>;
					als_deltap = <0x0a>;
					als_time = <0x7b>;
					d_factor = <0xb79b>;
					ch0_coef0 = <0x3e8>;
					ch1_coef0 = <0x1ed>;
					ch0_coef1 = <0x26b>;
					ch1_coef1 = <0xffffffe0>;
					az_iterations = <0x7e>;
					als_can_wake = <0x00>;
					boot-on;
					#address-cells = <0x01>;
					#size-cells = <0x01>;
					status = "okay";
					phandle = <0xe1>;
				};

				bl_extern_i2c {
					compatible = "amlogic, bl_extern_i2c";
					status = "disabled";
					reg = <0x2c>;
					dev_name = "lp8556";
				};
			};

			spi@13000 {
				compatible = "amlogic,meson-g12b-spicc\0amlogic,meson-g12a-spicc";
				reg = <0x00 0x13000 0x00 0x44>;
				interrupts = <0x00 0x51 0x04>;
				clocks = <0x0d 0x29 0x0d 0xd1>;
				clock-names = "core\0comp";
				#address-cells = <0x01>;
				#size-cells = <0x00>;
				status = "disabled";
				phandle = <0xe2>;
			};

			spi@15000 {
				compatible = "amlogic,meson-g12b-spicc\0amlogic,meson-g12a-spicc";
				reg = <0x00 0x15000 0x00 0x44>;
				interrupts = <0x00 0x5a 0x04>;
				clocks = <0x0d 0x2f 0x0d 0xd5>;
				clock-names = "core\0comp";
				#address-cells = <0x01>;
				#size-cells = <0x00>;
				status = "disabled";
				phandle = <0xe3>;
			};
		};

		aobus@ff800000 {
			compatible = "simple-bus";
			reg = <0x00 0xff800000 0x00 0xb000>;
			#address-cells = <0x02>;
			#size-cells = <0x02>;
			ranges = <0x00 0x00 0x00 0xff800000 0x00 0xb000>;
			phandle = <0xe4>;

			cpu_version {
				reg = <0x00 0x220 0x00 0x04>;
			};

			clock-controller@0 {
				compatible = "amlogic,g12b-aoclkc";
				#clock-cells = <0x01>;
				reg = <0x00 0x00 0x00 0x320>;
				phandle = <0xe5>;
			};

			pwm@7000 {
				compatible = "amlogic,g12b-ao-pwm";
				reg = <0x00 0x7000 0x00 0x20>;
				#pwm-cells = <0x03>;
				clocks = <0x27 0x27 0x27 0x27>;
				clock-names = "clkin0\0clkin1\0clkin2\0clkin3";
				status = "disabled";
				phandle = <0xe6>;
			};

			pwm@2000 {
				compatible = "amlogic,g12b-ao-pwm";
				reg = <0x00 0x2000 0x00 0x20>;
				#pwm-cells = <0x03>;
				clocks = <0x27 0x27 0x27 0x27>;
				clock-names = "clkin0\0clkin1\0clkin2\0clkin3";
				status = "okay";
				phandle = <0x57>;
			};

			i2c@5000 {
				compatible = "amlogic,meson-g12b-i2c";
				status = "okay";
				reg = <0x00 0x5000 0x00 0x20>;
				interrupts = <0x00 0xc3 0x01 0x00 0xc9 0x01>;
				#address-cells = <0x01>;
				#size-cells = <0x00>;
				clocks = <0x0d 0x2a>;
				clock-names = "clk_i2c";
				pinctrl-names = "default";
				pinctrl-0 = <0x2a>;
				clock-frequency = <0x55730>;
				phandle = <0xe7>;

				ina231@40 {
					compatible = "ti,ina231";
					reg = <0x40>;
					shunt-resistor = <0x3e8>;
				};

				tlv320aic32x4@18 {
					compatible = "ti,tlv320aic32x4";
					#sound-dai-cells = <0x00>;
					reg = <0x18>;
					reset-gpios = <0x26 0x3a 0x00>;
					amp-enable = <0x26 0x38 0x00>;
					status = "okay";
					phandle = <0x91>;
				};
			};

			i2c_slave@6000 {
				compatible = "amlogic, meson-i2c-slave";
				status = "disabled";
				reg = <0x00 0x6000 0x00 0x20>;
				interrupts = <0x00 0xc2 0x01>;
				pinctrl-names = "default";
				pinctrl-0 = <0x2b>;
				phandle = <0xe8>;
			};

			serial@3000 {
				compatible = "amlogic, meson-uart";
				reg = <0x00 0x3000 0x00 0x18>;
				interrupts = <0x00 0xc1 0x01>;
				status = "okay";
				clocks = <0x27>;
				clock-names = "clk_uart";
				xtal_tick_en = <0x02>;
				fifosize = <0x40>;
				pinctrl-names = "default";
				support-sysrq = <0x00>;
				phandle = <0xe9>;
			};

			serial@4000 {
				compatible = "amlogic, meson-uart";
				reg = <0x00 0x4000 0x00 0x18>;
				interrupts = <0x00 0xc5 0x01>;
				status = "disabled";
				clocks = <0x27>;
				clock-names = "clk_uart";
				fifosize = <0x40>;
				pinctrl-names = "default";
				pinctrl-0 = <0x2c>;
				phandle = <0xea>;
			};
		};

		periphs@ff634400 {
			compatible = "simple-bus";
			reg = <0x00 0xff634400 0x00 0x400>;
			#address-cells = <0x02>;
			#size-cells = <0x02>;
			ranges = <0x00 0x00 0x00 0xff634400 0x00 0x400>;
			phandle = <0xeb>;
		};

		hiubus@ff63c000 {
			compatible = "simple-bus";
			reg = <0x00 0xff63c000 0x00 0x2000>;
			#address-cells = <0x02>;
			#size-cells = <0x02>;
			ranges = <0x00 0x00 0x00 0xff63c000 0x00 0x2000>;
			phandle = <0xec>;

			clock-controller@0 {
				compatible = "amlogic,g12b-clkc-1";
				#clock-cells = <0x01>;
				reg = <0x00 0x00 0x00 0x3dc>;
				phandle = <0x0d>;
			};

			clock-controller@1 {
				compatible = "amlogic,g12b-clkc-2";
				#clock-cells = <0x01>;
				reg = <0x00 0x00 0x00 0x3dc>;
				phandle = <0xed>;
			};
		};

		ion_dev {
			compatible = "amlogic, ion_dev";
			memory-region = <0x2d>;
		};

		audiobus@0xff642000 {
			compatible = "amlogic, audio-controller\0simple-bus";
			reg = <0x00 0xff642000 0x00 0x2000>;
			#address-cells = <0x02>;
			#size-cells = <0x02>;
			ranges = <0x00 0x00 0x00 0xff642000 0x00 0x2000>;
			phandle = <0xee>;

			audio_clocks {
				compatible = "amlogic, g12a-audio-clocks";
				#clock-cells = <0x01>;
				reg = <0x00 0x00 0x00 0xb0>;
				phandle = <0x2e>;
			};

			ddr_manager {
				compatible = "amlogic, g12a-audio-ddr-manager";
				interrupts = <0x00 0x94 0x01 0x00 0x95 0x01 0x00 0x96 0x01 0x00 0x98 0x01 0x00 0x99 0x01 0x00 0x9a 0x01>;
				interrupt-names = "toddr_a\0toddr_b\0toddr_c\0frddr_a\0frddr_b\0frddr_c";
			};

			tdma {
				compatible = "amlogic, g12a-snd-tdma";
				#sound-dai-cells = <0x00>;
				dai-tdm-lane-slot-mask-in = <0x00 0x01>;
				dai-tdm-lane-slot-mask-out = <0x01 0x00>;
				dai-tdm-clk-sel = <0x00>;
				clocks = <0x2e 0x17 0x0d 0x0d>;
				clock-names = "mclk\0clk_srcpll";
				pinctrl-names = "tdm_pins";
				pinctrl-0 = <0x2f 0x30>;
				phandle = <0x8e>;
			};

			tdmb {
				compatible = "amlogic, g12a-snd-tdmb";
				#sound-dai-cells = <0x00>;
				#dai-tdm-lane-slot-mask-in = <0x00 0x01 0x00 0x00>;
				dai-tdm-lane-slot-mask-out = <0x01 0x00 0x00 0x00>;
				dai-tdm-clk-sel = <0x01>;
				clocks = <0x2e 0x18 0x0d 0x0d 0x0d 0x0c>;
				clock-names = "mclk\0clk_srcpll\0samesource_sysclk";
				mclk_pad = <0x00>;
				pinctrl-names = "tdm_pins";
				pinctrl-0 = <0x31 0x32>;
				#samesource_sel = <0x03>;
				phandle = <0x90>;
			};

			tdmc {
				compatible = "amlogic, g12a-snd-tdmc";
				#sound-dai-cells = <0x00>;
				dai-tdm-lane-slot-mask-in = <0x01 0x00 0x00 0x00>;
				#dai-tdm-lane-slot-mask-out = <0x01 0x00 0x01 0x01>;
				#dai-tdm-lane-oe-slot-mask-in = <0x00 0x00 0x00 0x00>;
				#dai-tdm-lane-oe-slot-mask-out = <0x01 0x00 0x00 0x00>;
				dai-tdm-clk-sel = <0x02>;
				clocks = <0x2e 0x19 0x0d 0x0d>;
				clock-names = "mclk\0clk_srcpll";
				pinctrl-names = "tdm_pins";
				pinctrl-0 = <0x33 0x34>;
				phandle = <0x92>;
			};

			i2s2hdmi {
				compatible = "amlogic, g12a-snd-tdmc-out";
				#sound-dai-cells = <0x00>;
				dai-tdm-lane-slot-mask-out = <0x01 0x01 0x01 0x01>;
				dai-tdm-clk-sel = <0x03>;
				clocks = <0x2e 0x1a 0x0d 0x0f>;
				clock-names = "mclk\0clk_srcpll";
				i2s2hdmi = <0x01>;
				status = "okay";
				phandle = <0x98>;
			};

			spdif_a {
				compatible = "amlogic, g12a-snd-spdif-a";
				#sound-dai-cells = <0x00>;
				clocks = <0x0d 0x0c 0x0d 0x04 0x2e 0x10 0x2e 0x11 0x2e 0x1d 0x2e 0x1e>;
				clock-names = "sysclk\0fixed_clk\0gate_spdifin\0gate_spdifout\0clk_spdifin\0clk_spdifout";
				interrupts = <0x00 0x97 0x01>;
				interrupt-names = "irq_spdifin";
				pinctrl-names = "spdif_pins";
				pinctrl-0 = <0x35>;
				status = "okay";
				phandle = <0x97>;
			};

			spdif_b {
				compatible = "amlogic, g12a-snd-spdif-b";
				#sound-dai-cells = <0x00>;
				clocks = <0x0d 0x0c 0x2e 0x15 0x2e 0x21>;
				clock-names = "sysclk\0gate_spdifout\0clk_spdifout";
				status = "disabled";
				phandle = <0xef>;
			};

			loopback {
				compatible = "amlogic, snd-loopback";
				lb_mode = <0x00>;
				datain_src = <0x02>;
				datain_chnum = <0x08>;
				datain_chmask = <0xff>;
				datalb_src = <0x01>;
				datalb_chnum = <0x02>;
				datalb_chmask = <0x01>;
				status = "okay";
				phandle = <0x8c>;
			};

			resample {
				compatible = "amlogic, g12a-resample";
				clocks = <0x0d 0x0f 0x2e 0x1c 0x2e 0x24>;
				clock-names = "resample_pll\0resample_src\0resample_clk";
				resample_module = <0x04>;
				status = "disabled";
				phandle = <0xf0>;
			};

			pwrdet {
				compatible = "amlogic, g12a-power-detect";
				interrupts = <0x00 0x9b 0x01>;
				interrupt-names = "pwrdet_irq";
				pwrdet_src = <0x04>;
				hi_th = <0x70000>;
				lo_th = <0x16000>;
				status = "disabled";
				phandle = <0xf1>;
			};
		};
	};

	rc@0xff808040 {
		compatible = "amlogic, aml_remote";
		dev_name = "meson-remote";
		reg = <0x00 0xff808040 0x00 0x44 0x00 0xff808000 0x00 0x20>;
		status = "okay";
		protocol = <0x0f>;
		interrupts = <0x00 0xc4 0x01>;
		pinctrl-names = "default";
		pinctrl-0 = <0x36>;
		map = <0x37>;
		max_frame_time = <0xc8>;
		phandle = <0xf2>;
	};

	custom_maps {
		mapnum = <0x00>;
		phandle = <0x37>;
	};

	serial@ffd24000 {
		compatible = "amlogic, meson-uart";
		reg = <0x00 0xffd24000 0x00 0x18>;
		interrupts = <0x00 0x1a 0x01>;
		status = "disabled";
		clocks = <0x27 0x0d 0x2e>;
		clock-names = "clk_uart\0clk_gate";
		fifosize = <0x80>;
		pinctrl-names = "default";
		pinctrl-0 = <0x38>;
		phandle = <0xf3>;
	};

	serial@ffd23000 {
		compatible = "amlogic, meson-uart";
		reg = <0x00 0xffd23000 0x00 0x18>;
		interrupts = <0x00 0x4b 0x01>;
		status = "disabled";
		clocks = <0x27 0x0d 0x3c>;
		clock-names = "clk_uart\0clk_gate";
		fifosize = <0x40>;
		pinctrl-names = "default";
		pinctrl-0 = <0x39>;
		phandle = <0xf4>;
	};

	serial@ffd22000 {
		compatible = "amlogic, meson-uart";
		reg = <0x00 0xffd22000 0x00 0x18>;
		interrupts = <0x00 0x5d 0x01>;
		status = "disabled";
		clocks = <0x27 0x0d 0x3c>;
		clock-names = "clk_uart\0clk_gate";
		fifosize = <0x40>;
		pinctrl-names = "default";
		pinctrl-0 = <0x3a>;
		phandle = <0xf5>;
	};

	pcieA@fc000000 {
		compatible = "amlogic, amlogic-pcie-v2\0snps,dw-pcie";
		reg = <0x00 0xfc000000 0x00 0x400000 0x00 0xff648000 0x00 0x2000 0x00 0xfc400000 0x00 0x200000 0x00 0xff646000 0x00 0x2000 0x00 0xffd01080 0x00 0x10>;
		reg-names = "elbi\0cfg\0config\0phy\0reset";
		interrupts = <0x00 0xdd 0x00>;
		#interrupt-cells = <0x01>;
		bus-range = <0x00 0xff>;
		#address-cells = <0x03>;
		#size-cells = <0x02>;
		interrupt-map-mask = <0x00 0x00 0x00 0x00>;
		interrupt-map = <0x00 0x00 0x00 0x00 0x01 0x00 0xdf 0x01>;
		device_type = "pci";
		ranges = <0x81000000 0x00 0x00 0x00 0xfc600000 0x00 0x100000 0x82000000 0x00 0xfc700000 0x00 0xfc700000 0x00 0x1900000>;
		num-lanes = <0x01>;
		pcie-num = <0x01>;
		clocks = <0x0d 0x18 0x0d 0x3f 0x0d 0x42>;
		clock-names = "pcie_refpll\0pcie\0pcie_phy";
		gpio-type = <0x02>;
		pcie-apb-rst-bit = <0x0f>;
		pcie-phy-rst-bit = <0x0e>;
		pcie-ctrl-a-rst-bit = <0x0c>;
		status = "disabled";
		phandle = <0xf6>;
	};

	amhdmitx {
		compatible = "amlogic, amhdmitx";
		dev_name = "amhdmitx";
		status = "okay";
		vend-data = <0x3b>;
		pinctrl-names = "default\0hdmitx_i2c";
		pinctrl-0 = <0x3c 0x3d>;
		pinctrl-1 = <0x3e 0x3f>;
		clocks = <0x0d 0x55 0x0d 0x4e 0x0d 0x4f 0x0d 0x95 0x0d 0x8c>;
		clock-names = "venci_top_gate\0venci_0_gate\0venci_1_gate\0hdmi_vapb_clk\0hdmi_vpu_clk";
		interrupts = <0x00 0x39 0x01>;
		interrupt-names = "hdmitx_hpd";
		ic_type = <0x0b>;
		hdmiocp-gpio = <0x26 0x3d 0x00>;
		phandle = <0xf7>;

		vend_data {
			vendor_name = "Amlogic";
			vendor_id = <0x00>;
			phandle = <0x3b>;
		};
	};

	galcore {
		compatible = "amlogic, galcore";
		dev_name = "galcore";
		status = "disabled";
		clocks = <0x0d 0xe8 0x0d 0xe7>;
		clock-names = "cts_vipnanoq_axi_clk_composite\0cts_vipnanoq_core_clk_composite";
		interrupts = <0x00 0x93 0x04>;
		interrupt-names = "galcore";
		reg = <0x00 0xff100000 0x00 0x800 0x00 0xff000000 0x00 0x400000>;
	};

	aocec {
		compatible = "amlogic, aocec-g12a";
		device_name = "aocec";
		status = "okay";
		vendor_name = "Amlogic";
		vendor_id = <0x00>;
		product_desc = "G12B";
		cec_osd_string = "AML_MBOX";
		port_num = <0x01>;
		arc_port_mask = <0x02>;
		interrupts = <0x00 0xcb 0x01 0x00 0xc7 0x01>;
		interrupt-names = "hdmi_aocecb\0hdmi_aocec";
		pinctrl-names = "default\0hdmitx_aocecb\0cec_pin_sleep";
		pinctrl-0 = <0x40>;
		pinctrl-1 = <0x41>;
		pinctrl-2 = <0x41>;
		reg = <0x00 0xff80023c 0x00 0x04 0x00 0xff800000 0x00 0x400 0x00 0xff634400 0x00 0x26>;
		reg-names = "ao_exit\0ao\0periphs";
		phandle = <0xf8>;
	};

	vdin0 {
		compatible = "amlogic, vdin";
		dev_name = "vdin0";
		status = "disabled";
		reserve-iomap = "true";
		flag_cma = <0x00>;
		interrupts = <0x00 0x53 0x01>;
		rdma-irq = <0x02>;
		vdin_id = <0x00>;
		tv_bit_mode = <0x15>;
		phandle = <0xf9>;
	};

	vdin1 {
		compatible = "amlogic, vdin";
		dev_name = "vdin1";
		status = "okay";
		reserve-iomap = "true";
		flag_cma = <0x00>;
		interrupts = <0x00 0x55 0x01>;
		rdma-irq = <0x04>;
		vdin_id = <0x01>;
		memory-region = <0x42>;
		tv_bit_mode = <0x01>;
		phandle = <0xfa>;
	};

	vout {
		compatible = "amlogic, vout";
		dev_name = "vout";
		status = "okay";
	};

	vout2 {
		compatible = "amlogic, vout2";
		dev_name = "vout";
		status = "okay";
		clocks = <0x0d 0xc4 0x0d 0xc9>;
		clock-names = "vpu_clkc0\0vpu_clkc";
	};

	vdac {
		compatible = "amlogic, vdac-g12b";
		status = "okay";
	};

	canvas {
		compatible = "amlogic, meson, canvas";
		dev_name = "amlogic-canvas";
		status = "okay";
		reg = <0x00 0xff638000 0x00 0x2000>;
		phandle = <0xfb>;
	};

	ge2d {
		compatible = "amlogic, ge2d-g12a";
		dev_name = "ge2d";
		status = "okay";
		interrupts = <0x00 0x92 0x01>;
		interrupt-names = "ge2d";
		clocks = <0x0d 0x95 0x0d 0x3d 0x0d 0x96>;
		clock-names = "clk_vapb_0\0clk_ge2d\0clk_ge2d_gate";
		reg = <0x00 0xff940000 0x00 0x10000>;
	};

	meson-amvideom {
		compatible = "amlogic, amvideom";
		dev_name = "amvideom";
		status = "okay";
		interrupts = <0x00 0x03 0x01>;
		interrupt-names = "vsync";
	};

	codec_io {
		compatible = "amlogic, codec_io";
		status = "okay";
		#address-cells = <0x02>;
		#size-cells = <0x02>;
		ranges;
		phandle = <0xfc>;

		io_cbus_base {
			reg = <0x00 0xffd00000 0x00 0x100000>;
		};

		io_dos_base {
			reg = <0x00 0xff620000 0x00 0x10000>;
		};

		io_hiubus_base {
			reg = <0x00 0xff63c000 0x00 0x2000>;
		};

		io_aobus_base {
			reg = <0x00 0xff800000 0x00 0x10000>;
		};

		io_vcbus_base {
			reg = <0x00 0xff900000 0x00 0x40000>;
		};

		io_dmc_base {
			reg = <0x00 0xff638000 0x00 0x2000>;
		};

		io_efuse_base {
			reg = <0x00 0xff630000 0x00 0x2000>;
		};
	};

	gdc {
		#address-cells = <0x02>;
		#size-cells = <0x02>;
		status = "ok";
		compatible = "amlogic, g12b-gdc";
		reg = <0x00 0xff950000 0x00 0x100 0x00 0xff63c16c 0x00 0x04 0x00 0xff63c100 0x00 0x04>;
		interrupts = <0x00 0x90 0x01>;
		interrupt-names = "GDC";
		clocks = <0x0d 0xe5 0x0d 0xe6>;
		clock-names = "core\0axi";
		phandle = <0xfd>;
	};

	mesonstream {
		compatible = "amlogic, codec, streambuf";
		dev_name = "mesonstream";
		status = "okay";
		clocks = <0x0d 0x40 0x0d 0x39 0x0d 0x43 0x0d 0x22 0x0d 0xa5 0x0d 0xae 0x0d 0xb7 0x0d 0xc0>;
		clock-names = "parser_top\0demux\0ahbarb0\0vdec\0clk_vdec_mux\0clk_hcodec_mux\0clk_hevc_mux\0clk_hevcb_mux";
	};

	vdec {
		compatible = "amlogic, vdec";
		dev_name = "vdec.0";
		status = "okay";
		interrupts = <0x00 0x03 0x01 0x00 0x17 0x01 0x00 0x20 0x01 0x00 0x2b 0x01 0x00 0x2c 0x01 0x00 0x2d 0x01>;
		interrupt-names = "vsync\0demux\0parser\0mailbox_0\0mailbox_1\0mailbox_2";
	};

	amvenc_avc {
		compatible = "amlogic, amvenc_avc";
		dev_name = "amvenc_avc";
		status = "okay";
		interrupts = <0x00 0x2d 0x01>;
		interrupt-names = "mailbox_2";
	};

	hevc_enc {
		compatible = "cnm, HevcEnc";
		dev_name = "HevcEnc";
		status = "okay";
		interrupts = <0x00 0xbb 0x01>;
		interrupt-names = "wave420l_irq";
		#address-cells = <0x02>;
		#size-cells = <0x02>;
		ranges;

		io_reg_base {
			reg = <0x00 0xff610000 0x00 0x4000>;
		};
	};

	rdma {
		compatible = "amlogic, meson-g12b, rdma";
		dev_name = "amlogic-rdma";
		status = "okay";
		interrupts = <0x00 0x59 0x01>;
		interrupt-names = "rdma";
	};

	meson-fb {
		compatible = "amlogic, meson-g12b";
		memory-region = <0x43>;
		dev_name = "meson-fb";
		status = "okay";
		interrupts = <0x00 0x03 0x01 0x00 0x38 0x01 0x00 0x59 0x01>;
		interrupt-names = "viu-vsync\0viu2-vsync\0rdma";
		display_mode_default = "1080p60hz";
		scale_mode = <0x01>;
		display_size_default = <0x780 0x438 0x780 0x870 0x20>;
		clocks = <0x0d 0xc9>;
		clock-names = "vpu_clkc";
		mem_size = <0x800000 0x1980000 0x100000 0x100000 0x800000>;
		logo_addr = "0x7f800000";
		mem_alloc = <0x00>;
		pxp_mode = <0x00>;
		phandle = <0xfe>;
	};

	meson-irblaster {
		compatible = "amlogic, meson_irblaster";
		dev_name = "irblaster";
		reg = <0x00 0xff80014c 0x00 0x10 0x00 0xff800040 0x00 0x04>;
		pinctrl-names = "default";
		pinctrl-0 = <0x44>;
		io-channels = <0x45 0x01>;
		enable_pin = <0x26 0x19 0x00>;
		irdetect-gpio = <0x26 0x18 0x00>;
		irfaultdetect-gpio = <0x26 0x17 0x01>;
		interrupts = <0x00 0xc6 0x01>;
		status = "okay";
		phandle = <0xff>;
	};

	emmc@ffe07000 {
		status = "okay";
		compatible = "amlogic, meson-mmc-g12b";
		reg = <0x00 0xffe07000 0x00 0x800>;
		interrupts = <0x00 0xbf 0x01>;
		pinctrl-names = "emmc_clk_cmd_pins\0emmc_all_pins";
		pinctrl-0 = <0x46>;
		pinctrl-1 = <0x47 0x48>;
		clocks = <0x0d 0x35 0x0d 0x72 0x0d 0x02 0x0d 0x20 0x27>;
		clock-names = "core\0clkin0\0clkin1\0clkin2\0xtal";
		bus-width = <0x08>;
		cap-sd-highspeed;
		cap-mmc-highspeed;
		max-frequency = <0xbebc200>;
		non-removable;
		disable-wp;
		phandle = <0x100>;

		emmc {
			pinname = "emmc";
			ocr_avail = <0x200080>;
			tx_delay = <0x00>;
			max_req_size = <0x20000>;
			gpio_dat3 = <0x26 0x1d 0x00>;
			hw_reset = <0x26 0x23 0x00>;
			card_type = <0x01>;
			caps = "MMC_CAP_8_BIT_DATA\0MMC_CAP_MMC_HIGHSPEED\0MMC_CAP_SD_HIGHSPEED\0MMC_CAP_NONREMOVABLE\0MMC_CAP_1_8V_DDR\0MMC_CAP_HW_RESET\0MMC_CAP_ERASE\0MMC_CAP_CMD23\0MMC_CAP_DRIVER_TYPE_A";
			caps2 = "MMC_CAP2_HS200\0MMC_CAP2_HS400";
			f_min = <0x61a80>;
			f_max = <0xbebc200>;
		};
	};

	sd@ffe05000 {
		status = "okay";
		compatible = "amlogic, meson-mmc-g12b";
		reg = <0x00 0xffe05000 0x00 0x800>;
		interrupts = <0x00 0xbe 0x04>;
		pinctrl-names = "sd_all_pins\0sd_clk_cmd_pins\0sd_1bit_pins\0sd_clk_cmd_uart_pins\0sd_1bit_uart_pins\0sd_to_ao_uart_pins\0ao_to_sd_uart_pins\0sd_to_ao_jtag_pins\0ao_to_sd_jtag_pins";
		pinctrl-0 = <0x49>;
		pinctrl-1 = <0x4a>;
		pinctrl-2 = <0x4b>;
		pinctrl-3 = <0x4c 0x4a 0x4d>;
		pinctrl-4 = <0x4c 0x4b 0x4d>;
		pinctrl-5 = <0x49 0x4e>;
		pinctrl-6 = <0x4c 0x4d>;
		pinctrl-7 = <0x49 0x4e>;
		pinctrl-8 = <0x4c 0x4d>;
		clocks = <0x0d 0x34 0x0d 0x6e 0x0d 0x02 0x0d 0x05 0x27>;
		clock-names = "core\0clkin0\0clkin1\0clkin2\0xtal";
		bus-width = <0x04>;
		cap-sd-highspeed;
		cap-mmc-highspeed;
		max-frequency = <0x5f5e100>;
		disable-wp;
		phandle = <0x101>;

		sd {
			pinname = "sd";
			ocr_avail = <0x200080>;
			max_req_size = <0x20000>;
			gpio_dat3 = <0x26 0x2d 0x00>;
			jtag_pin = <0x26 0x2a 0x00>;
			gpio_cd = <0x26 0x30 0x00>;
			card_type = <0x05>;
			caps = "MMC_CAP_4_BIT_DATA\0MMC_CAP_MMC_HIGHSPEED\0MMC_CAP_SD_HIGHSPEED\0MMC_CAP_UHS_SDR12\0MMC_CAP_UHS_SDR25\0MMC_CAP_UHS_SDR50\0MMC_CAP_UHS_SDR104";
			vol_switch_def = <0x26 0x53 0x00>;
			vol_switch = <0x26 0x55 0x00>;
			vol_switch_delay = <0x96>;
			f_min = <0x61a80>;
			f_max = <0xbebc200>;
		};

		sdio {
			caps = "MMC_CAP_4_BIT_DATA\0MMC_CAP_MMC_HIGHSPEED\0MMC_CAP_SD_HIGHSPEED\0MMC_CAP_NONREMOVABLE\0MMC_CAP_UHS_SDR12\0MMC_CAP_UHS_SDR25\0MMC_CAP_UHS_SDR50\0MMC_CAP_UHS_SDR104\0MMC_PM_KEEP_POWER\0MMC_CAP_SDIO_IRQ";
			f_min = <0x61a80>;
			f_max = <0xbebc200>;
		};
	};

	sdio@ffe03000 {
		status = "okay";
		compatible = "amlogic, meson-mmc-g12b";
		reg = <0x00 0xffe03000 0x00 0x800>;
		interrupts = <0x00 0xbd 0x04>;
		pinctrl-names = "sdio_all_pins\0sdio_clk_cmd_pins";
		pinctrl-0 = <0x4f>;
		pinctrl-1 = <0x50>;
		clocks = <0x0d 0x33 0x0d 0x6a 0x0d 0x02 0x0d 0x05 0x27>;
		clock-names = "core\0clkin0\0clkin1\0clkin2\0xtal";
		bus-width = <0x04>;
		cap-sd-highspeed;
		cap-mmc-highspeed;
		max-frequency = <0x5f5e100>;
		disable-wp;
		mt76x8_pmu_en_gpio = <0x26 0x51 0x00>;
		phandle = <0x102>;

		sdio {
			pinname = "sdio";
			ocr_avail = <0x200080>;
			max_req_size = <0x20000>;
			card_type = <0x03>;
			caps = "MMC_CAP_4_BIT_DATA\0MMC_CAP_MMC_HIGHSPEED\0MMC_CAP_SD_HIGHSPEED\0MMC_CAP_NONREMOVABLE\0MMC_CAP_UHS_SDR12\0MMC_CAP_UHS_SDR25\0MMC_CAP_UHS_SDR50\0MMC_CAP_UHS_SDR104\0MMC_PM_KEEP_POWER\0MMC_CAP_SDIO_IRQ";
			f_min = <0x61a80>;
			f_max = <0xbebc200>;
		};
	};

	nfc@0 {
		compatible = "amlogic, aml_mtd_nand";
		dev_name = "mtdnand";
		status = "disabled";
		reg = <0x00 0xffe07800 0x00 0x200>;
		interrupts = <0x00 0x22 0x01>;
		pinctrl-names = "nand_rb_mod\0nand_norb_mod\0nand_cs_only";
		pinctrl-0 = <0x51>;
		pinctrl-1 = <0x51>;
		pinctrl-2 = <0x52>;
		clocks = <0x0d 0x35 0x0d 0x72>;
		clock-names = "core\0clkin";
		device_id = <0x00>;
		bl_mode = <0x01>;
		fip_copies = <0x04>;
		fip_size = <0x200000>;
		nand_clk_ctrl = <0xffe07000>;
		plat-names = "bootloader\0nandnormal";
		plat-num = <0x02>;
		plat-part-0 = <0x53>;
		plat-part-1 = <0x54>;
		phandle = <0x103>;

		bootloader {
			enable_pad = "ce0";
			busy_pad = "rb0";
			timming_mode = "mode5";
			bch_mode = "bch8_1k";
			t_rea = <0x14>;
			t_rhoh = <0x0f>;
			chip_num = <0x01>;
			part_num = <0x00>;
			rb_detect = <0x01>;
			phandle = <0x53>;
		};

		nandnormal {
			enable_pad = "ce0";
			busy_pad = "rb0";
			timming_mode = "mode5";
			bch_mode = "bch8_1k";
			plane_mode = "twoplane";
			t_rea = <0x14>;
			t_rhoh = <0x0f>;
			chip_num = <0x02>;
			part_num = <0x03>;
			partition = <0x55>;
			rb_detect = <0x01>;
			phandle = <0x54>;
		};

		nand_partition {
			phandle = <0x55>;

			tpl {
				offset = <0x00 0x00>;
				size = <0x00 0x00>;
			};

			logo {
				offset = <0x00 0x00>;
				size = <0x00 0x200000>;
			};

			recovery {
				offset = <0x00 0x00>;
				size = <0x00 0x1000000>;
			};

			boot {
				offset = <0x00 0x00>;
				size = <0x00 0x1000000>;
			};

			system {
				offset = <0x00 0x00>;
				size = <0x00 0x4000000>;
			};

			data {
				offset = <0xffffffff 0xffffffff>;
				size = <0x00 0x00>;
			};
		};
	};

	meson-cooldev@0 {
		status = "okay";
		compatible = "amlogic, meson-cooldev";
		device_name = "mcooldev";
		phandle = <0x104>;

		cooling_devices {

			cpufreq_cool_cluster0 {
				min_state = <0xf4240>;
				dyn_coeff = <0x78>;
				cluster_id = <0x00>;
				gpu_pp = <0x02>;
				node_name = "cpufreq_cool0";
				device_type = "cpufreq";
			};

			cpufreq_cool_cluster1 {
				min_state = <0xf4240>;
				dyn_coeff = <0x1cc>;
				cluster_id = <0x01>;
				gpu_pp = <0x02>;
				node_name = "cpufreq_cool1";
				device_type = "cpufreq";
			};

			cpucore_cool_cluster0 {
				min_state = <0x01>;
				dyn_coeff = <0x00>;
				cluster_id = <0x00>;
				gpu_pp = <0x02>;
				node_name = "cpucore_cool0";
				device_type = "cpucore";
			};

			cpucore_cool_cluster1 {
				min_state = <0x00>;
				dyn_coeff = <0x00>;
				cluster_id = <0x01>;
				gpu_pp = <0x02>;
				node_name = "cpucore_cool1";
				device_type = "cpucore";
			};

			gpufreq_cool {
				min_state = <0x190>;
				dyn_coeff = <0x166>;
				cluster_id = <0x00>;
				gpu_pp = <0x02>;
				node_name = "gpufreq_cool0";
				device_type = "gpufreq";
			};

			gpucore_cool {
				min_state = <0x01>;
				dyn_coeff = <0x00>;
				cluster_id = <0x00>;
				gpu_pp = <0x02>;
				node_name = "gpucore_cool0";
				device_type = "gpucore";
			};
		};

		cpufreq_cool0 {
			#cooling-cells = <0x02>;
			phandle = <0x105>;
		};

		cpufreq_cool1 {
			#cooling-cells = <0x02>;
			phandle = <0x5f>;
		};

		cpucore_cool0 {
			#cooling-cells = <0x02>;
			phandle = <0x106>;
		};

		cpucore_cool1 {
			#cooling-cells = <0x02>;
			phandle = <0x64>;
		};

		gpufreq_cool0 {
			#cooling-cells = <0x02>;
			phandle = <0x63>;
		};

		gpucore_cool0 {
			#cooling-cells = <0x02>;
			phandle = <0x65>;
		};
	};

	aml_snd_iomap {
		compatible = "amlogic, snd-iomap";
		status = "okay";
		#address-cells = <0x02>;
		#size-cells = <0x02>;
		ranges;

		pdm_bus {
			reg = <0x00 0xff640000 0x00 0x2000>;
		};

		audiobus_base {
			reg = <0x00 0xff642000 0x00 0x2000>;
		};

		audiolocker_base {
			reg = <0x00 0xff64a000 0x00 0x2000>;
		};

		eqdrc_base {
			reg = <0x00 0xff656000 0x00 0x1800>;
		};

		reset_base {
			reg = <0x00 0xffd01000 0x00 0x1000>;
		};
	};

	pwmao_d-regulator {
		compatible = "pwm-regulator";
		pinctrl-names = "default";
		pinctrl-0 = <0x56>;
		pwms = <0x57 0x01 0x4e2 0x00>;
		regulator-name = "vddcpu0";
		regulator-min-microvolt = <0xb0068>;
		regulator-max-microvolt = <0xf9830>;
		regulator-always-on;
		max-duty-cycle = <0x4e2>;
		voltage-table = <0xf9830 0x00 0xf6d38 0x03 0xf4628 0x06 0xf1f18 0x0a 0xef808 0x0d 0xed0f8 0x10 0xea9e8 0x14 0xe82d8 0x17 0xe5bc8 0x1a 0xe34b8 0x1e 0xe0da8 0x21 0xde698 0x24 0xdbf88 0x28 0xd9878 0x2b 0xd7168 0x2e 0xd4a58 0x32 0xd2348 0x35 0xcfc38 0x38 0xcd528 0x3c 0xcae18 0x3f 0xc8708 0x43 0xc5ff8 0x46 0xc38e8 0x49 0xc11d8 0x4c 0xbeac8 0x50 0xbc3b8 0x53 0xb9ca8 0x56 0xb7598 0x5a 0xb4e88 0x5d 0xb2778 0x60 0xb0068 0x64>;
		status = "okay";
		phandle = <0x1c>;
	};

	pwmab_a-regulator {
		compatible = "pwm-regulator";
		pinctrl-names = "default";
		pinctrl-0 = <0x58>;
		pwms = <0x59 0x00 0x4e2 0x00>;
		regulator-name = "vddcpu1";
		regulator-min-microvolt = <0xb0068>;
		regulator-max-microvolt = <0xf9830>;
		regulator-always-on;
		max-duty-cycle = <0x4e2>;
		voltage-table = <0xf9830 0x00 0xf6d38 0x03 0xf4628 0x06 0xf1f18 0x0a 0xef808 0x0d 0xed0f8 0x10 0xea9e8 0x14 0xe82d8 0x17 0xe5bc8 0x1a 0xe34b8 0x1e 0xe0da8 0x21 0xde698 0x24 0xdbf88 0x28 0xd9878 0x2b 0xd7168 0x2e 0xd4a58 0x32 0xd2348 0x35 0xcfc38 0x38 0xcd528 0x3c 0xcae18 0x3f 0xc8708 0x43 0xc5ff8 0x46 0xc38e8 0x49 0xc11d8 0x4c 0xbeac8 0x50 0xbc3b8 0x53 0xb9ca8 0x56 0xb7598 0x5a 0xb4e88 0x5d 0xb2778 0x60 0xb0068 0x64>;
		status = "okay";
		phandle = <0x20>;
	};

	rng {
		compatible = "amlogic,meson-rng";
		status = "okay";
		#address-cells = <0x02>;
		#size-cells = <0x02>;
		reg = <0x00 0xff630218 0x00 0x04>;
		quality = [03 e8];
	};

	ddr_bandwidth {
		compatible = "amlogic, ddr-bandwidth";
		status = "okay";
		reg = <0x00 0xff638000 0x00 0x100 0x00 0xff638c00 0x00 0x100>;
		interrupts = <0x00 0x34 0x01>;
		interrupt-names = "ddr_bandwidth";
	};

	dmc_monitor {
		compatible = "amlogic, dmc_monitor";
		status = "okay";
		reg_base = <0xff639000>;
		interrupts = <0x00 0x33 0x01>;
	};

	isp-sc@ff655400 {
		compatible = "amlogic, isp-sc";
		reg = <0x00 0xff655400 0x00 0x1000>;
		reg-names = "isp_sc";
		interrupts = <0x00 0x11 0x00>;
		interrupt-names = "isp_sc";
		phandle = <0x5a>;
	};

	isp@ff140000 {
		compatible = "arm, isp";
		reg = <0x00 0xff140000 0x00 0x40000>;
		reg-names = "ISP";
		interrupts = <0x00 0x8e 0x04>;
		interrupt-names = "ISP";
		temper-buf-size = <0x18>;
		clocks = <0x0d 0xea 0x0d 0xeb>;
		clock-names = "cts_mipi_isp_clk_composite\0cts_mipi_csi_phy_clk0_composite";
		link-device = <0x5a>;
		phandle = <0x107>;
	};

	isp-adapter@ff650000 {
		compatible = "amlogic, isp-adapter";
		reg = <0x00 0xff650000 0x00 0x6000>;
		reg-names = "adapter";
		interrupts = <0x00 0xb3 0x00>;
		interrupt-names = "adapter-irq";
		mem_alloc = <0x30>;
		phandle = <0x5b>;
	};

	phy-csi@ff650000 {
		compatible = "amlogic, phy-csi";
		reg = <0x00 0xff650000 0x00 0x2000 0x00 0xff652000 0x00 0x2000 0x00 0xff63c300 0x00 0x100 0x00 0xff654000 0x00 0x100 0x00 0xff654400 0x00 0x100>;
		reg-names = "csi2_phy0\0csi2_phy1\0aphy_reg\0csi0_host\0csi1_host";
		interrupts = <0x00 0x29 0x00 0x00 0x2a 0x00 0x00 0x48 0x00 0x00 0x4a 0x00 0x00 0x57 0x00 0x00 0x58 0x00>;
		interrupt-names = "phy0-irq\0phy1-irq\0csi-host0-intr2\0csi-host0-intr1\0csi-host1-intr2\0csi-host1-intr1";
		link-device = <0x5b>;
		phandle = <0x108>;
	};

	efuse {
		compatible = "amlogic, efuse";
		read_cmd = <0x82000030>;
		write_cmd = <0x82000031>;
		get_max_cmd = <0x82000033>;
		key = <0x5c>;
		clocks = <0x0d 0x61>;
		clock-names = "efuse_clk";
		status = "okay";
		phandle = <0x109>;
	};

	defendkey {
		compatible = "amlogic, defendkey";
		reg = <0x00 0xff630218 0x00 0x04>;
		mem_size = <0x00 0x100000>;
		status = "okay";
		phandle = <0x10a>;
	};

	thermal-zones {

		soc_thermal {
			polling-delay = <0x3e8>;
			polling-delay-passive = <0x64>;
			sustainable-power = <0xdde>;
			policy = "trip_step_wise";
			thermal-sensors = <0x5d 0x00>;
			phandle = <0x10b>;

			trips {

				trip-point@0 {
					temperature = <0x14c08>;
					hysteresis = <0x3e8>;
					type = "passive";
					phandle = <0x5e>;
				};

				trip-point@1 {
					temperature = <0x15f90>;
					hysteresis = <0x3e8>;
					type = "passive";
					phandle = <0x60>;
				};

				trip-point@2 {
					temperature = <0x17318>;
					hysteresis = <0x3e8>;
					type = "passive";
					phandle = <0x61>;
				};

				trip-point@3 {
					temperature = <0x186a0>;
					hysteresis = <0x3e8>;
					type = "passive";
					phandle = <0x62>;
				};

				trip-point@4 {
					temperature = <0x1adb0>;
					hysteresis = <0x3e8>;
					type = "critical";
					phandle = <0x10c>;
				};
			};

			cooling-maps {

				cpufreq_cooling_map0 {
					trip = <0x5e>;
					cooling-device = <0x5f 0x00 0x02>;
					contribution = <0x400>;
				};

				cpufreq_cooling_map1 {
					trip = <0x60>;
					cooling-device = <0x5f 0x02 0x04>;
					contribution = <0x400>;
				};

				cpufreq_cooling_map2 {
					trip = <0x61>;
					cooling-device = <0x5f 0x04 0x07>;
					contribution = <0x400>;
				};

				cpufreq_cooling_map3 {
					trip = <0x62>;
					cooling-device = <0x5f 0x07 0x09>;
					contribution = <0x400>;
				};

				gpufreq_cooling_map0 {
					trip = <0x5e>;
					cooling-device = <0x63 0x00 0x00>;
					contribution = <0x400>;
				};

				gpufreq_cooling_map1 {
					trip = <0x60>;
					cooling-device = <0x63 0x00 0x03>;
					contribution = <0x400>;
				};

				gpufreq_cooling_map2 {
					trip = <0x61>;
					cooling-device = <0x63 0x03 0x03>;
					contribution = <0x400>;
				};

				gpufreq_cooling_map3 {
					trip = <0x62>;
					cooling-device = <0x63 0x03 0x04>;
					contribution = <0x400>;
				};

				cpucore_cooling_map0 {
					trip = <0x5e>;
					cooling-device = <0x64 0x00 0x00>;
					contribution = <0x400>;
				};

				cpucore_cooling_map1 {
					trip = <0x60>;
					cooling-device = <0x64 0x00 0x00>;
					contribution = <0x400>;
				};

				cpucore_cooling_map2 {
					trip = <0x61>;
					cooling-device = <0x64 0x00 0x01>;
					contribution = <0x400>;
				};

				cpucore_cooling_map3 {
					trip = <0x62>;
					cooling-device = <0x64 0x01 0x02>;
					contribution = <0x400>;
				};

				gpucore_cooling_map0 {
					trip = <0x5e>;
					cooling-device = <0x65 0x00 0x00>;
					contribution = <0x400>;
				};

				gpucore_cooling_map1 {
					trip = <0x60>;
					cooling-device = <0x65 0x00 0x00>;
					contribution = <0x400>;
				};

				gpucore_cooling_map2 {
					trip = <0x61>;
					cooling-device = <0x65 0x00 0x01>;
					contribution = <0x400>;
				};

				gpucore_cooling_map3 {
					trip = <0x62>;
					cooling-device = <0x65 0x01 0x02>;
					contribution = <0x400>;
				};

				wifi_cooling_map0 {
					trip = <0x5e>;
					cooling-device = <0x66 0x00 0x00>;
					contribution = <0x400>;
				};

				wifi_cooling_map1 {
					trip = <0x60>;
					cooling-device = <0x66 0x00 0x00>;
					contribution = <0x400>;
				};

				wifi_cooling_map2 {
					trip = <0x61>;
					cooling-device = <0x66 0x00 0x01>;
					contribution = <0x400>;
				};

				wifi_cooling_map3 {
					trip = <0x62>;
					cooling-device = <0x66 0x01 0x02>;
					contribution = <0x400>;
				};
			};
		};

		ddr_thermal {
			polling-delay = <0x3e8>;
			polling-delay-passive = <0x64>;
			sustainable-power = <0xdde>;
			thermal-sensors = <0x67 0x01>;
			phandle = <0x10d>;

			trips {

				trip-point@0 {
					temperature = <0xea60>;
					hysteresis = <0x1388>;
					type = "passive";
					phandle = <0x10e>;
				};

				trip-point@1 {
					temperature = <0x124f8>;
					hysteresis = <0x1388>;
					type = "passive";
					phandle = <0x10f>;
				};

				trip-point@2 {
					temperature = <0x14c08>;
					hysteresis = <0x1388>;
					type = "hot";
					phandle = <0x110>;
				};

				trip-point@3 {
					temperature = <0x249f0>;
					hysteresis = <0x3e8>;
					type = "critical";
					phandle = <0x111>;
				};
			};
		};

		board_thermal1 {
			polling-delay = <0x3e8>;
			polling-delay-passive = <0x64>;
			sustainable-power = <0x866>;
			policy = "trip_step_wise";
			thermal-sensors = <0x68>;

			trips {

				trip-point@0 {
					temperature = <0xdea8>;
					hysteresis = <0x3e8>;
					type = "passive";
					phandle = <0x69>;
				};

				trip-point@1 {
					temperature = <0xe290>;
					hysteresis = <0x3e8>;
					type = "passive";
					phandle = <0x6a>;
				};

				trip-point@2 {
					temperature = <0xe678>;
					hysteresis = <0x3e8>;
					type = "passive";
					phandle = <0x6b>;
				};

				trip-point@3 {
					temperature = <0xea60>;
					hysteresis = <0x3e8>;
					type = "passive";
					phandle = <0x6c>;
				};

				trip-point@4 {
					temperature = <0xf230>;
					hysteresis = <0x3e8>;
					type = "critical";
					phandle = <0x112>;
				};
			};

			cooling-maps {

				cpufreq_cooling_map0 {
					trip = <0x69>;
					cooling-device = <0x5f 0x00 0x02>;
					contribution = <0x400>;
				};

				cpufreq_cooling_map1 {
					trip = <0x6a>;
					cooling-device = <0x5f 0x02 0x04>;
					contribution = <0x400>;
				};

				cpufreq_cooling_map2 {
					trip = <0x6b>;
					cooling-device = <0x5f 0x04 0x07>;
					contribution = <0x400>;
				};

				cpufreq_cooling_map3 {
					trip = <0x6c>;
					cooling-device = <0x5f 0x07 0x09>;
					contribution = <0x400>;
				};

				gpufreq_cooling_map0 {
					trip = <0x69>;
					cooling-device = <0x63 0x00 0x00>;
					contribution = <0x400>;
				};

				gpufreq_cooling_map1 {
					trip = <0x6a>;
					cooling-device = <0x63 0x00 0x00>;
					contribution = <0x400>;
				};

				gpufreq_cooling_map2 {
					trip = <0x6b>;
					cooling-device = <0x63 0x03 0x03>;
					contribution = <0x400>;
				};

				gpufreq_cooling_map3 {
					trip = <0x6c>;
					cooling-device = <0x63 0x03 0x04>;
					contribution = <0x400>;
				};

				cpucore_cooling_map0 {
					trip = <0x69>;
					cooling-device = <0x64 0x00 0x00>;
					contribution = <0x400>;
				};

				cpucore_cooling_map1 {
					trip = <0x6a>;
					cooling-device = <0x64 0x00 0x00>;
					contribution = <0x400>;
				};

				cpucore_cooling_map2 {
					trip = <0x6b>;
					cooling-device = <0x64 0x00 0x01>;
					contribution = <0x400>;
				};

				cpucore_cooling_map3 {
					trip = <0x6c>;
					cooling-device = <0x64 0x01 0x02>;
					contribution = <0x400>;
				};

				gpucore_cooling_map0 {
					trip = <0x69>;
					cooling-device = <0x65 0x00 0x00>;
					contribution = <0x400>;
				};

				gpucore_cooling_map1 {
					trip = <0x6a>;
					cooling-device = <0x65 0x00 0x00>;
					contribution = <0x400>;
				};

				gpucore_cooling_map2 {
					trip = <0x6b>;
					cooling-device = <0x65 0x00 0x01>;
					contribution = <0x400>;
				};

				gpucore_cooling_map3 {
					trip = <0x6c>;
					cooling-device = <0x65 0x01 0x02>;
					contribution = <0x400>;
				};

				wifi_cooling_map0 {
					trip = <0x69>;
					cooling-device = <0x66 0x00 0x00>;
					contribution = <0x400>;
				};

				wifi_cooling_map1 {
					trip = <0x6a>;
					cooling-device = <0x66 0x00 0x00>;
					contribution = <0x400>;
				};

				wifi_cooling_map2 {
					trip = <0x6b>;
					cooling-device = <0x66 0x00 0x01>;
					contribution = <0x400>;
				};

				wifi_cooling_map3 {
					trip = <0x6c>;
					cooling-device = <0x66 0x01 0x02>;
					contribution = <0x400>;
				};
			};
		};

		board_thermal2 {
			polling-delay = <0x3e8>;
			polling-delay-passive = <0x64>;
			sustainable-power = <0x866>;
			policy = "trip_step_wise";
			thermal-sensors = <0x6d>;

			trips {

				trip-point@0 {
					temperature = <0xdea8>;
					hysteresis = <0x3e8>;
					type = "passive";
					phandle = <0x6e>;
				};

				trip-point@1 {
					temperature = <0xe290>;
					hysteresis = <0x3e8>;
					type = "passive";
					phandle = <0x6f>;
				};

				trip-point@2 {
					temperature = <0xe678>;
					hysteresis = <0x3e8>;
					type = "passive";
					phandle = <0x70>;
				};

				trip-point@3 {
					temperature = <0xea60>;
					hysteresis = <0x3e8>;
					type = "passive";
					phandle = <0x71>;
				};

				trip-point@4 {
					temperature = <0xf230>;
					hysteresis = <0x3e8>;
					type = "critical";
					phandle = <0x113>;
				};
			};

			cooling-maps {

				cpufreq_cooling_map0 {
					trip = <0x6e>;
					cooling-device = <0x5f 0x00 0x02>;
					contribution = <0x400>;
				};

				cpufreq_cooling_map1 {
					trip = <0x6f>;
					cooling-device = <0x5f 0x02 0x04>;
					contribution = <0x400>;
				};

				cpufreq_cooling_map2 {
					trip = <0x70>;
					cooling-device = <0x5f 0x04 0x07>;
					contribution = <0x400>;
				};

				cpufreq_cooling_map3 {
					trip = <0x71>;
					cooling-device = <0x5f 0x07 0x09>;
					contribution = <0x400>;
				};

				gpufreq_cooling_map0 {
					trip = <0x6e>;
					cooling-device = <0x63 0x00 0x00>;
					contribution = <0x400>;
				};

				gpufreq_cooling_map1 {
					trip = <0x6f>;
					cooling-device = <0x63 0x00 0x03>;
					contribution = <0x400>;
				};

				gpufreq_cooling_map2 {
					trip = <0x70>;
					cooling-device = <0x63 0x03 0x03>;
					contribution = <0x400>;
				};

				gpufreq_cooling_map3 {
					trip = <0x71>;
					cooling-device = <0x63 0x03 0x04>;
					contribution = <0x400>;
				};

				cpucore_cooling_map0 {
					trip = <0x6e>;
					cooling-device = <0x64 0x00 0x00>;
					contribution = <0x400>;
				};

				cpucore_cooling_map1 {
					trip = <0x6f>;
					cooling-device = <0x64 0x00 0x00>;
					contribution = <0x400>;
				};

				cpucore_cooling_map2 {
					trip = <0x70>;
					cooling-device = <0x64 0x00 0x01>;
					contribution = <0x400>;
				};

				cpucore_cooling_map3 {
					trip = <0x71>;
					cooling-device = <0x64 0x01 0x02>;
					contribution = <0x400>;
				};

				gpucore_cooling_map0 {
					trip = <0x6e>;
					cooling-device = <0x65 0x00 0x00>;
					contribution = <0x400>;
				};

				gpucore_cooling_map1 {
					trip = <0x6f>;
					cooling-device = <0x65 0x00 0x00>;
					contribution = <0x400>;
				};

				gpucore_cooling_map2 {
					trip = <0x70>;
					cooling-device = <0x65 0x00 0x01>;
					contribution = <0x400>;
				};

				gpucore_cooling_map3 {
					trip = <0x71>;
					cooling-device = <0x65 0x01 0x02>;
					contribution = <0x400>;
				};

				wifi_cooling_map0 {
					trip = <0x6e>;
					cooling-device = <0x66 0x00 0x00>;
					contribution = <0x400>;
				};

				wifi_cooling_map1 {
					trip = <0x6f>;
					cooling-device = <0x66 0x00 0x00>;
					contribution = <0x400>;
				};

				wifi_cooling_map2 {
					trip = <0x70>;
					cooling-device = <0x66 0x00 0x01>;
					contribution = <0x400>;
				};

				wifi_cooling_map3 {
					trip = <0x71>;
					cooling-device = <0x66 0x01 0x02>;
					contribution = <0x400>;
				};
			};
		};

		wifi_thermal {
			polling-delay = <0x3e8>;
			polling-delay-passive = <0x64>;
			sustainable-power = <0x866>;
			policy = "trip_step_wise";
			thermal-sensors = <0x72>;

			trips {

				trip-point@0 {
					temperature = <0xee48>;
					hysteresis = <0x3e8>;
					type = "passive";
					phandle = <0x73>;
				};

				trip-point@1 {
					temperature = <0x3f7a0>;
					hysteresis = <0x3e8>;
					type = "critical";
					phandle = <0x74>;
				};
			};

			cooling-maps {

				wifi_cooling_map0 {
					trip = <0x73>;
					cooling-device = <0x66 0x00 0x01>;
					contribution = <0x400>;
				};

				wifi_cooling_map1 {
					trip = <0x74>;
					cooling-device = <0x66 0x01 0x01>;
					contribution = <0x400>;
				};
			};
		};
	};

	aliases {
		serial0 = "/soc/aobus@ff800000/serial@3000";
		serial1 = "/serial@ffd24000";
		serial2 = "/serial@ffd23000";
		serial3 = "/serial@ffd22000";
		serial4 = "/soc/aobus@ff800000/serial@4000";
		i2c0 = "/soc/cbus@ffd00000/i2c@1f000";
		i2c1 = "/soc/cbus@ffd00000/i2c@1e000";
		i2c2 = "/soc/cbus@ffd00000/i2c@1d000";
		i2c3 = "/soc/cbus@ffd00000/i2c@1c000";
		i2c4 = "/soc/aobus@ff800000/i2c@5000";
		tsensor0 = "/p_tsensor@ff634594";
		tsensor1 = "/d_tsensor@ff800228";
	};

	memory@00000000 {
		device_type = "memory";
		linux,usable-memory = <0x00 0x100000 0x00 0x7ff00000>;
	};

	reserved-memory {
		#address-cells = <0x02>;
		#size-cells = <0x02>;
		ranges;

		ramoops@0x07400000 {
			compatible = "ramoops";
			reg = <0x00 0x7400000 0x00 0x100000>;
			record-size = <0x8000>;
			console-size = <0x8000>;
			ftrace-size = <0x00>;
			pmsg-size = <0x8000>;
		};

		linux,secmon {
			compatible = "shared-dma-pool";
			reusable;
			size = <0x00 0x2400000>;
			alignment = <0x00 0x400000>;
			alloc-ranges = <0x00 0x5000000 0x00 0x2400000>;
			clear-map;
			phandle = <0x21>;
		};

		linux,secos {
			status = "disable";
			compatible = "amlogic, aml_secos_memory";
			reg = <0x00 0x5300000 0x00 0x2000000>;
			no-map;
			phandle = <0x114>;
		};

		linux,meson-fb {
			compatible = "shared-dma-pool";
			reusable;
			size = <0x00 0x800000>;
			alignment = <0x00 0x400000>;
			alloc-ranges = <0x00 0x7f800000 0x00 0x800000>;
			phandle = <0x43>;
		};

		linux,ion-dev {
			compatible = "shared-dma-pool";
			reusable;
			size = <0x00 0x8000000>;
			alignment = <0x00 0x400000>;
			phandle = <0x2d>;
		};

		linux,di_cma {
			compatible = "shared-dma-pool";
			reusable;
			size = <0x00 0x2800000>;
			alignment = <0x00 0x400000>;
			phandle = <0x78>;
		};

		linux,codec_mm_cma {
			compatible = "shared-dma-pool";
			reusable;
			size = <0x00 0x13400000>;
			alignment = <0x00 0x400000>;
			linux,contiguous-region;
			clear-map;
			phandle = <0x76>;
		};

		linux,codec_mm_reserved {
			compatible = "amlogic, codec-mm-reserved";
			size = <0x00 0x00>;
			alignment = <0x00 0x100000>;
			phandle = <0x77>;
		};

		linux,vdin1_cma {
			compatible = "shared-dma-pool";
			reusable;
			size = <0x00 0x1000000>;
			alignment = <0x00 0x400000>;
			phandle = <0x42>;
		};
	};

	cvbsout {
		compatible = "amlogic, cvbsout-g12b";
		dev_name = "cvbsout";
		status = "okay";
		clocks = <0x0d 0x55 0x0d 0x4e 0x0d 0x4f 0x0d 0x57>;
		clock-names = "venci_top_gate\0venci_0_gate\0venci_1_gate\0vdac_clk_gate";
		clk_path = <0x00>;
		performance = <0x1bf0 0x09 0x1b56 0x333 0x1b12 0x8080 0x1b05 0xfd 0x1c59 0xf850 0xffff 0x00>;
		performance_sarft = <0x1bf0 0x09 0x1b56 0x333 0x1b12 0x00 0x1b05 0x09 0x1c59 0xfc48 0xffff 0x00>;
	};

	bt-dev {
		compatible = "amlogic, bt-dev";
		dev_name = "bt-dev";
		status = "okay";
		gpio_en = <0x26 0x50 0x00>;
	};

	wifi {
		compatible = "amlogic, aml_wifi";
		dev_name = "aml_wifi";
		status = "okay";
		interrupt_pin = <0x26 0x49 0x00>;
		irq_trigger_type = "GPIO_IRQ_LOW";
		power_on_pin = <0x26 0x51 0x00>;
		power_pin_reset = <0x01>;
	};

	wifi_pwm_conf {
		phandle = <0x115>;

		pwm_channel1_conf {
			pwms = <0x75 0x00 0x7558 0x00>;
			duty-cycle = <0x3aac>;
			times = <0x0a>;
		};

		pwm_channel2_conf {
			pwms = <0x75 0x02 0x754e 0x00>;
			duty-cycle = <0x3aa7>;
			times = <0x0c>;
		};
	};

	codec_mm {
		compatible = "amlogic, codec, mm";
		memory-region = <0x76 0x77>;
		dev_name = "codec_mm";
		status = "okay";
	};

	deinterlace {
		compatible = "amlogic, deinterlace";
		status = "okay";
		flag_cma = <0x01>;
		memory-region = <0x78>;
		interrupts = <0x00 0x2e 0x01 0x00 0x28 0x01>;
		interrupt-names = "pre_irq\0post_irq";
		clocks = <0x0d 0x9b 0x0d 0x9c>;
		clock-names = "vpu_clkb_tmp_composite\0vpu_clkb_composite";
		clock-range = <0x14e 0x29b>;
		buffer-size = <0x3e2c40>;
		post-wr-support = <0x01>;
		nr10bit-support = <0x01>;
		nrds-enable = <0x01>;
		pps-enable = <0x01>;
	};

	ionvideo {
		compatible = "amlogic, ionvideo";
		dev_name = "ionvideo";
		status = "okay";
	};

	gpio_keypad {
		compatible = "amlogic, gpio_keypad";
		status = "okay";
		scan_period = <0x14>;
		key_num = <0x04>;
		key_name = "mute\0action\0volup\0voldown";
		key_code = <0x71 0x8a 0x72 0x73>;
		key_pin = <0x26 0x52 0x00 0x26 0x48 0x00 0x26 0x4e 0x00 0x26 0x4f 0x00>;
		interrupts = <0x00 0x46 0x01 0x00 0x47 0x02>;
		interrupt-names = "irq_keyup\0irq_keydown";
	};

	amz_privacy {
		gpios = <0x26 0x3b 0x00>;
	};

	adc_keypad {
		compatible = "amlogic, adc_keypad";
		status = "disable";
		key_name = "up\0down\0left\0right";
		key_num = <0x04>;
		io-channels = <0x45 0x02>;
		io-channel-names = "key-chan-2";
		key_chan = <0x02 0x02 0x02 0x02>;
		key_code = <0x67 0x6c 0x69 0x6a>;
		key_val = <0x00 0x8d 0x111 0x188>;
		key_tolerance = <0x28 0x28 0x28 0x28>;
	};

	unifykey {
		compatible = "amlogic, unifykey";
		status = "ok";
		unifykey-num = <0x0f>;
		unifykey-index-0 = <0x79>;
		unifykey-index-1 = <0x7a>;
		unifykey-index-2 = <0x7b>;
		unifykey-index-3 = <0x7c>;
		unifykey-index-4 = <0x7d>;
		unifykey-index-5 = <0x7e>;
		unifykey-index-6 = <0x7f>;
		unifykey-index-7 = <0x80>;
		unifykey-index-8 = <0x81>;
		unifykey-index-9 = <0x82>;
		unifykey-index-10 = <0x83>;
		unifykey-index-11 = <0x84>;
		unifykey-index-12 = <0x85>;
		unifykey-index-13 = <0x86>;
		unifykey-index-14 = <0x87>;

		key_0 {
			key-name = "usid";
			key-device = "normal";
			key-permit = "read\0write\0del";
			phandle = <0x79>;
		};

		key_1 {
			key-name = "mac";
			key-device = "normal";
			key-permit = "read\0write\0del";
			phandle = <0x7a>;
		};

		key_2 {
			key-name = "hdcp";
			key-device = "secure";
			key-type = "sha1";
			key-permit = "read\0write\0del";
			phandle = <0x7b>;
		};

		key_3 {
			key-name = "secure_boot_set";
			key-device = "efuse";
			key-permit = "write";
			phandle = <0x7c>;
		};

		key_4 {
			key-name = "mac_bt";
			key-device = "normal";
			key-permit = "read\0write\0del";
			key-type = "mac";
			phandle = <0x7d>;
		};

		key_5 {
			key-name = "mac_wifi";
			key-device = "normal";
			key-permit = "read\0write\0del";
			key-type = "mac";
			phandle = <0x7e>;
		};

		key_6 {
			key-name = "hdcp2_tx";
			key-device = "normal";
			key-permit = "read\0write\0del";
			phandle = <0x7f>;
		};

		key_7 {
			key-name = "hdcp2_rx";
			key-device = "normal";
			key-permit = "read\0write\0del";
			phandle = <0x80>;
		};

		key_8 {
			key-name = "widevinekeybox";
			key-device = "secure";
			key-permit = "read\0write\0del";
			phandle = <0x81>;
		};

		key_9 {
			key-name = "deviceid";
			key-device = "normal";
			key-permit = "read\0write\0del";
			phandle = <0x82>;
		};

		key_10 {
			key-name = "hdcp22_fw_private";
			key-device = "secure";
			key-permit = "read\0write\0del";
			phandle = <0x83>;
		};

		key_11 {
			key-name = "PlayReadykeybox25";
			key-device = "secure";
			key-permit = "read\0write\0del";
			phandle = <0x84>;
		};

		key_12 {
			key-name = "prpubkeybox";
			key-device = "secure";
			key-permit = "read\0write\0del";
			phandle = <0x85>;
		};

		key_13 {
			key-name = "prprivkeybox";
			key-device = "secure";
			key-permit = "read\0write\0del";
			phandle = <0x86>;
		};

		key_14 {
			key-name = "attestationkeybox";
			key-device = "secure";
			key-permit = "read\0write\0del";
			phandle = <0x87>;
		};
	};

	efusekey {
		keynum = <0x04>;
		key0 = <0x88>;
		key1 = <0x89>;
		key2 = <0x8a>;
		key3 = <0x8b>;
		phandle = <0x5c>;

		key_0 {
			keyname = "mac";
			offset = <0x00>;
			size = <0x06>;
			phandle = <0x88>;
		};

		key_1 {
			keyname = "mac_bt";
			offset = <0x06>;
			size = <0x06>;
			phandle = <0x89>;
		};

		key_2 {
			keyname = "mac_wifi";
			offset = <0x0c>;
			size = <0x06>;
			phandle = <0x8a>;
		};

		key_3 {
			keyname = "usid";
			offset = <0x12>;
			size = <0x10>;
			phandle = <0x8b>;
		};
	};

	amlvecm {
		compatible = "amlogic, vecm";
		dev_name = "aml_vecm";
		status = "okay";
		gamma_en = <0x00>;
		wb_en = <0x00>;
		cm_en = <0x00>;
	};

	amdolby_vision {
		compatible = "amlogic, dolby_vision_g12a";
		dev_name = "aml_amdolby_vision_driver";
		status = "okay";
		tv_mode = <0x00>;
	};

	dummy {
		#sound-dai-cells = <0x00>;
		compatible = "amlogic, aml_dummy_codec";
		status = "okay";
		phandle = <0x8f>;
	};

	eqdrc {
		eqdrc_module = <0x01>;
		lane_mask = <0x01>;
		channel_mask = <0x03>;
		phandle = <0x8d>;
	};

	auge_sound {
		compatible = "amlogic, g12a-sound-card";
		aml-audio-card,name = "AML-AUGESOUND";
		aml-audio-card,loopback = <0x8c>;
		aml-audio-card,effect = <0x8d>;

		aml-audio-card,dai-link@0 {
			format = "i2s";
			mclk-fs = <0x100>;
			bitclock-master = <0x8e>;
			frame-master = <0x8e>;
			suffix-name = "alsaPORT-pcm";

			cpu {
				sound-dai = <0x8e>;
				dai-tdm-slot-tx-mask = <0x01 0x01>;
				dai-tdm-slot-rx-mask = <0x01 0x01>;
				dai-tdm-slot-num = <0x02>;
				dai-tdm-slot-width = <0x20>;
				system-clock-frequency = <0xbb8000>;
				phandle = <0x116>;
			};

			codec {
				sound-dai = <0x8f 0x8f>;
				phandle = <0x117>;
			};
		};

		aml-audio-card,dai-link@1 {
			format = "i2s";
			mclk-fs = <0x100>;
			continuous-clock;
			bitclock-master = <0x90>;
			frame-master = <0x90>;
			suffix-name = "alsaPORT-i2s";

			cpu {
				sound-dai = <0x90>;
				dai-tdm-slot-tx-mask = <0x01 0x01>;
				dai-tdm-slot-rx-mask = <0x01 0x01>;
				dai-tdm-slot-num = <0x02>;
				dai-tdm-slot-width = <0x20>;
				system-clock-frequency = <0xbb8000>;
			};

			codec {
				sound-dai = <0x91>;
				phandle = <0x118>;
			};
		};

		aml-audio-card,dai-link@2 {
			format = "dsp_b";
			mclk-fs = <0x100>;
			bitclock-master = <0x92>;
			frame-master = <0x92>;
			suffix-name = "alsaPORT-tdm";

			cpu {
				sound-dai = <0x92>;
				dai-tdm-slot-tx-mask = <0x01 0x01 0x01 0x01 0x01 0x01 0x01 0x01>;
				dai-tdm-slot-rx-mask = <0x01 0x01 0x01 0x01 0x01 0x01 0x01 0x01>;
				dai-tdm-slot-num = <0x08>;
				dai-tdm-slot-width = <0x18>;
				system-clock-frequency = <0xbb8000>;
			};

			codec {
				sound-dai = <0x93 0x94 0x95 0x96>;
				dai-tdm-slot-tx-mask = <0x01 0x01 0x01 0x01 0x01 0x01 0x01 0x01>;
				dai-tdm-slot-rx-mask = <0x01 0x01 0x01 0x01 0x01 0x01 0x01 0x01>;
				dai-tdm-slot-num = <0x10>;
				dai-tdm-slot-width = <0x18>;
				phandle = <0x119>;
			};
		};

		aml-audio-card,dai-link@5 {
			mclk-fs = <0x80>;
			suffix-name = "alsaPORT-spdif";

			cpu {
				sound-dai = <0x97>;
				system-clock-frequency = <0x5dc000>;
			};

			codec {
				sound-dai = <0x8f>;
			};
		};

		aml-audio-card,dai-link@6 {
			format = "i2s";
			mclk-fs = <0x100>;
			bitclock-master = <0x98>;
			frame-master = <0x98>;
			suffix-name = "alsaPORT-i2s2hdmi";

			cpu {
				sound-dai = <0x98>;
				dai-tdm-slot-tx-mask = <0x01 0x01>;
				dai-tdm-slot-num = <0x02>;
				dai-tdm-slot-width = <0x20>;
				system-clock-frequency = <0xbb8000>;
			};

			codec {
				sound-dai = <0x8f>;
			};
		};
	};

	cpu_opp_table0 {
		compatible = "operating-points-v2";
		opp-shared;
		phandle = <0x1b>;

		opp00 {
			opp-hz = <0x00 0x5f5e100>;
			opp-microvolt = <0xb2778>;
		};

		opp01 {
			opp-hz = <0x00 0xee6b280>;
			opp-microvolt = <0xb2778>;
		};

		opp02 {
			opp-hz = <0x00 0x1dcd6500>;
			opp-microvolt = <0xb2778>;
		};

		opp03 {
			opp-hz = <0x00 0x27c19cc0>;
			opp-microvolt = <0xb2778>;
		};

		opp04 {
			opp-hz = <0x00 0x3b9aca00>;
			opp-microvolt = <0xb9ca8>;
		};

		opp05 {
			opp-hz = <0x00 0x47868c00>;
			opp-microvolt = <0xbeac8>;
		};

		opp06 {
			opp-hz = <0x00 0x5353c980>;
			opp-microvolt = <0xc5ff8>;
		};

		opp07 {
			opp-hz = <0x00 0x5a1f4a00>;
			opp-microvolt = <0xd2348>;
		};

		opp08 {
			opp-hz = <0x00 0x5fd82200>;
			opp-microvolt = <0xdbf88>;
		};

		opp09 {
			opp-hz = <0x00 0x6590fa00>;
			opp-microvolt = <0xe82d8>;
		};

		opp10 {
			opp-hz = <0x00 0x71b9c500>;
			opp-microvolt = <0xf9830>;
		};
	};

	cpu_opp_table1 {
		compatible = "operating-points-v2";
		opp-shared;
		phandle = <0x1f>;

		opp00 {
			opp-hz = <0x00 0x5f5e100>;
			opp-microvolt = <0xb2778>;
		};

		opp01 {
			opp-hz = <0x00 0xee6b280>;
			opp-microvolt = <0xb2778>;
		};

		opp02 {
			opp-hz = <0x00 0x1dcd6500>;
			opp-microvolt = <0xb2778>;
		};

		opp03 {
			opp-hz = <0x00 0x27c19cc0>;
			opp-microvolt = <0xb2778>;
		};

		opp04 {
			opp-hz = <0x00 0x3b9aca00>;
			opp-microvolt = <0xb2778>;
		};

		opp05 {
			opp-hz = <0x00 0x47868c00>;
			opp-microvolt = <0xb7598>;
		};

		opp06 {
			opp-hz = <0x00 0x5353c980>;
			opp-microvolt = <0xbc3b8>;
		};

		opp07 {
			opp-hz = <0x00 0x5a1f4a00>;
			opp-microvolt = <0xbc3b8>;
		};

		opp08 {
			opp-hz = <0x00 0x5fd82200>;
			opp-microvolt = <0xbeac8>;
		};

		opp09 {
			opp-hz = <0x00 0x6590fa00>;
			opp-microvolt = <0xc11d8>;
		};

		opp10 {
			opp-hz = <0x00 0x6b49d200>;
			opp-microvolt = <0xcae18>;
		};

		opp11 {
			opp-hz = <0x00 0x71b9c500>;
			opp-microvolt = <0xd2348>;
		};

		opp12 {
			opp-hz = <0x00 0x7829b800>;
			opp-microvolt = <0xde698>;
		};

		opp13 {
			opp-hz = <0x00 0x7d2b7500>;
			opp-microvolt = <0xe82d8>;
		};

		opp14 {
			opp-hz = <0x00 0x839b6800>;
			opp-microvolt = <0xf6d38>;
		};
	};

	cpufreq-meson {
		compatible = "amlogic, cpufreq-meson";
		status = "okay";
	};

	thermistor0 {
		compatible = "amlogic,thermistor";
		status = "okay";
		pull_up_resistor = <0x2710>;
		over_critical_low = <0x2fc44>;
		pull_up_voltage = <0x708>;
		ntc_table = <0x07>;
		adc_channel = <0x00>;
		io-channels = <0x45 0x02>;
		io-channel-names = "THERMISTOR_CHAN";
		phandle = <0x11a>;
	};

	thermistor1 {
		compatible = "amlogic,thermistor";
		status = "okay";
		pull_up_resistor = <0x2710>;
		over_critical_low = <0x2fc44>;
		pull_up_voltage = <0x708>;
		ntc_table = <0x07>;
		adc_channel = <0x01>;
		io-channels = <0x45 0x03>;
		io-channel-names = "THERMISTOR_CHAN";
		phandle = <0x11b>;
	};

	thermistor2 {
		compatible = "amlogic,thermistor";
		status = "okay";
		pull_up_resistor = <0x2710>;
		over_critical_low = <0x2fc44>;
		pull_up_voltage = <0x708>;
		ntc_table = <0x07>;
		adc_channel = <0x02>;
		io-channels = <0x45 0x00>;
		io-channel-names = "THERMISTOR_CHAN";
		phandle = <0x11c>;
	};

	wifi-sensor {
		compatible = "amazon,wifi_temp_sensor";
		#thermal-sensor-cells = <0x00>;
		vs_name = "wifi_sensor";
		offset = <0x00>;
		alpha = <0x00>;
		weight = <0x12c>;
		phandle = <0x72>;
	};

	virtual-sensor {
		compatible = "amazon,virtual_sensor";
		#thermal-sensor-cells = <0x00>;
		phandle = <0x68>;

		vs_components {

			vs_thermistor0 {
				vs_name = "thermistor0";
				offset = <0xffff9624>;
				alpha = <0x32>;
				weight = <0xd6>;
			};

			vs_thermistor1 {
				vs_name = "thermistor1";
				offset = <0x3138>;
				alpha = <0x01>;
				weight = <0x131>;
			};

			vs_thermistor2 {
				vs_name = "thermistor2";
				offset = <0xffff7cc0>;
				alpha = <0x27>;
				weight = <0xe5>;
			};
		};

		cooling_devices {

			wificool {
				min_state = <0x00>;
				node_name = "wifi_cool";
				device_type = "wifi";
			};
		};

		wifi_cool {
			#cooling-cells = <0x02>;
			phandle = <0x66>;
		};
	};

	virtual-sensor2 {
		compatible = "amazon,virtual_sensor";
		#thermal-sensor-cells = <0x00>;
		phandle = <0x6d>;

		vs_components {

			vs_thermistor0 {
				vs_name = "thermistor0";
				offset = <0xfffffb14>;
				alpha = <0x1a8>;
				weight = <0x69>;
			};

			vs_thermistor1 {
				vs_name = "thermistor1";
				offset = <0xffffc824>;
				alpha = <0x2d2>;
				weight = <0x19c>;
			};

			vs_thermistor2 {
				vs_name = "thermistor2";
				offset = <0xffff6f14>;
				alpha = <0x00>;
				weight = <0xad>;
			};
		};
	};

	__symbols__ {
		partitions = "/partitions";
		boot = "/partitions/boot";
		recovery = "/partitions/recovery";
		logo = "/partitions/logo";
		tee = "/partitions/tee";
		misc = "/partitions/misc";
		vendor = "/partitions/vendor";
		odm = "/partitions/odm";
		system = "/partitions/system";
		product = "/partitions/product";
		cache = "/partitions/cache";
		data = "/partitions/data";
		gpu = "/bifrost";
		dvfs125_cfg = "/bifrost/clk125_cfg";
		dvfs250_cfg = "/bifrost/dvfs250_cfg";
		dvfs285_cfg = "/bifrost/dvfs285_cfg";
		dvfs400_cfg = "/bifrost/dvfs400_cfg";
		dvfs500_cfg = "/bifrost/dvfs500_cfg";
		dvfs666_cfg = "/bifrost/dvfs666_cfg";
		dvfs800_cfg = "/bifrost/dvfs800_cfg";
		dvfs850_cfg = "/bifrost/dvfs850_cfg";
		CPU_COST_A73 = "/energy-costs/core-cost0";
		CPU_COST_A53 = "/energy-costs/core-cost1";
		CLUSTER_COST_A73 = "/energy-costs/cluster-cost0";
		CLUSTER_COST_A53 = "/energy-costs/cluster-cost1";
		cpus = "/cpus";
		cluster0 = "/cpus/cpu-map/cluster0";
		cluster1 = "/cpus/cpu-map/cluster1";
		CPU0 = "/cpus/cpu@0";
		CPU1 = "/cpus/cpu@1";
		CPU2 = "/cpus/cpu@100";
		CPU3 = "/cpus/cpu@101";
		CPU4 = "/cpus/cpu@102";
		CPU5 = "/cpus/cpu@103";
		CPU_SLEEP_0 = "/cpus/idle-states/cpu-sleep-0";
		CLUSTER_SLEEP_0 = "/cpus/idle-states/cluster-sleep-0";
		gic = "/interrupt-controller@2c001000";
		meson_suspend = "/pm";
		mailbox = "/mhu@c883c400";
		xtal = "/xtal-clk";
		ethmac = "/ethernet@ff3f0000";
		pinctrl_aobus = "/pinctrl@ff800014";
		gpio_ao = "/pinctrl@ff800014/ao-bank@ff800014";
		ao_uart_pins = "/pinctrl@ff800014/ao_uart";
		ao_b_uart_pins = "/pinctrl@ff800014/ao_b_uart";
		ao_i2c_master_pins1 = "/pinctrl@ff800014/ao_i2c_pins1";
		ao_i2c_master_pins2 = "/pinctrl@ff800014/ao_i2c_pins2";
		ao_i2c_slave_pins = "/pinctrl@ff800014/ao_i2c_slave_pins";
		pwm_ao_a_pins = "/pinctrl@ff800014/pwm_ao_a";
		pwm_ao_a_hiz_pins = "/pinctrl@ff800014/pwm_ao_a_hiz";
		pwm_ao_b_pins = "/pinctrl@ff800014/pwm_ao_b";
		pwm_ao_c_pins1 = "/pinctrl@ff800014/pwm_ao_c_pins1";
		pwm_ao_c_pins2 = "/pinctrl@ff800014/pwm_ao_c_pins2";
		pwm_ao_c_hiz_pins = "/pinctrl@ff800014/pwm_ao_c_hiz";
		pwm_ao_d_pins1 = "/pinctrl@ff800014/pwm_ao_d_pins1";
		pwm_ao_d_pins2 = "/pinctrl@ff800014/pwm_ao_d_pins2";
		pwm_ao_d_pins3 = "/pinctrl@ff800014/pwm_ao_d_pins3";
		aocec_a = "/pinctrl@ff800014/ao_ceca";
		aocec_b = "/pinctrl@ff800014/ao_cecb";
		pwm_a_e2 = "/pinctrl@ff800014/pwm_a_e2";
		sd_to_ao_uart_clr_pins = "/pinctrl@ff800014/sd_to_ao_uart_clr_pins";
		sd_to_ao_uart_pins = "/pinctrl@ff800014/sd_to_ao_uart_pins";
		remote_pins = "/pinctrl@ff800014/remote_pin";
		irblaster_pins = "/pinctrl@ff800014/irblaster_pin";
		irblaster_pins1 = "/pinctrl@ff800014/irblaster_pin1";
		pinctrl_periphs = "/pinctrl@ff634480";
		gpio = "/pinctrl@ff634480/banks@ff6346c0";
		emmc_clk_cmd_pins = "/pinctrl@ff634480/emmc_clk_cmd_pins";
		emmc_conf_pull_up = "/pinctrl@ff634480/emmc_conf_pull_up";
		emmc_conf_pull_done = "/pinctrl@ff634480/emmc_conf_pull_done";
		sd_clk_cmd_pins = "/pinctrl@ff634480/sd_clk_cmd_pins";
		sd_all_pins = "/pinctrl@ff634480/sd_all_pins";
		sd_1bit_pins = "/pinctrl@ff634480/sd_1bit_pins";
		ao_to_sd_uart_pins = "/pinctrl@ff634480/ao_to_sd_uart_pins";
		sdio_clk_cmd_pins = "/pinctrl@ff634480/sdio_clk_cmd_pins";
		sdio_all_pins = "/pinctrl@ff634480/sdio_all_pins";
		all_nand_pins = "/pinctrl@ff634480/all_nand_pins";
		nand_cs_pins = "/pinctrl@ff634480/nand_cs";
		i2c0_master_pins1 = "/pinctrl@ff634480/i2c0_pins1";
		i2c0_master_pins2 = "/pinctrl@ff634480/i2c0_pins2";
		i2c0_master_pins3 = "/pinctrl@ff634480/i2c0_pins3";
		i2c1_master_pins1 = "/pinctrl@ff634480/i2c1_pins1";
		i2c1_master_pins2 = "/pinctrl@ff634480/i2c1_pins2";
		i2c1_master_pins3 = "/pinctrl@ff634480/i2c1_pins3";
		i2c2_master_pins1 = "/pinctrl@ff634480/i2c2_pins1";
		i2c2_master_pins2 = "/pinctrl@ff634480/i2c2_pins2";
		i2c3_master_pins1 = "/pinctrl@ff634480/i2c3_pins1";
		i2c3_master_pins2 = "/pinctrl@ff634480/i2c3_pins2";
		pwm_a_pins = "/pinctrl@ff634480/pwm_a";
		pwm_b_pins1 = "/pinctrl@ff634480/pwm_b_pins1";
		pwm_b_pins2 = "/pinctrl@ff634480/pwm_b_pins2";
		pwm_b_pins3 = "/pinctrl@ff634480/pwm_b_pins3";
		pwm_b_pins4 = "/pinctrl@ff634480/pwm_b_pins4";
		pwm_b_pins5 = "/pinctrl@ff634480/pwm_b_pins5";
		pwm_c_pins1 = "/pinctrl@ff634480/pwm_c_pins1";
		pwm_c_pins2 = "/pinctrl@ff634480/pwm_c_pins2";
		pwm_c_pins3 = "/pinctrl@ff634480/pwm_c_pins3";
		pwm_c_pins4 = "/pinctrl@ff634480/pwm_c_pins4";
		pwm_d_pins1 = "/pinctrl@ff634480/pwm_d_pins1";
		pwm_d_pins2 = "/pinctrl@ff634480/pwm_d_pins2";
		pwm_d_pins3 = "/pinctrl@ff634480/pwm_d_pins3";
		pwm_d_pins4 = "/pinctrl@ff634480/pwm_d_pins4";
		pwm_e_pins = "/pinctrl@ff634480/pwm_e";
		pwm_f_pins1 = "/pinctrl@ff634480/pwm_f_pins1";
		pwm_f_pins2 = "/pinctrl@ff634480/pwm_f_pins2";
		pwm_f_pins3 = "/pinctrl@ff634480/pwm_f_pins3";
		pwm_f_pins4 = "/pinctrl@ff634480/pwm_f_pins4";
		spicc0_pins_x = "/pinctrl@ff634480/spicc0_pins_x";
		spicc1_pins = "/pinctrl@ff634480/spicc1_pins";
		a_uart_pins = "/pinctrl@ff634480/a_uart";
		b_uart_pins = "/pinctrl@ff634480/b_uart";
		c_uart_pins = "/pinctrl@ff634480/c_uart";
		hdmitx_hpd = "/pinctrl@ff634480/hdmitx_hpd";
		hdmitx_hpd_gpio = "/pinctrl@ff634480/hdmitx_hpd_gpio";
		hdmitx_ddc = "/pinctrl@ff634480/hdmitx_ddc";
		eecec_a = "/pinctrl@ff634480/ee_ceca";
		eecec_b = "/pinctrl@ff634480/ee_cecb";
		internal_eth_pins = "/pinctrl@ff634480/internal_eth_pins";
		external_eth_pins = "/pinctrl@ff634480/external_eth_pins";
		irblaster_pins2 = "/pinctrl@ff634480/irblaster_pins2";
		irblaster_pins3 = "/pinctrl@ff634480/irblaster_pins3";
		tdmout_a = "/pinctrl@ff634480/tdmout_a";
		tdmin_a = "/pinctrl@ff634480/tdmin_a";
		tdmb_mclk = "/pinctrl@ff634480/tdmb_mclk";
		tdmout_b = "/pinctrl@ff634480/tdmout_b";
		tdmc_mclk = "/pinctrl@ff634480/tdmc_mclk";
		tdmout_c = "/pinctrl@ff634480/tdmout_c";
		tdmin_c = "/pinctrl@ff634480/tdmin_c";
		spdifin = "/pinctrl@ff634480/spdifin";
		audio_data = "/audio_data";
		dwc3 = "/dwc3@ff500000";
		usb2_phy_v2 = "/usb2phy@ffe09000";
		usb3_phy_v2 = "/usb3phy@ffe09080";
		dwc2_a = "/dwc2_a@ff400000";
		wdt = "/watchdog@0xffd0f0d0";
		saradc = "/saradc";
		p_tsensor = "/p_tsensor@ff634594";
		d_tsensor = "/d_tsensor@ff800228";
		cbus = "/soc/cbus@ffd00000";
		gpio_intc = "/soc/cbus@ffd00000/interrupt-controller@f080";
		pwm_ab = "/soc/cbus@ffd00000/pwm@1b000";
		pwm_cd = "/soc/cbus@ffd00000/pwm@1a000";
		pwm_ef = "/soc/cbus@ffd00000/pwm@19000";
		i2c0 = "/soc/cbus@ffd00000/i2c@1f000";
		i2c1 = "/soc/cbus@ffd00000/i2c@1e000";
		i2c2 = "/soc/cbus@ffd00000/i2c@1d000";
		i2c3 = "/soc/cbus@ffd00000/i2c@1c000";
		tlv320adc3101_30 = "/soc/cbus@ffd00000/i2c@1c000/tlv320adc3101_30@30";
		tlv320adc3101_32 = "/soc/cbus@ffd00000/i2c@1c000/tlv320adc3101_32@32";
		tlv320adc3101_34 = "/soc/cbus@ffd00000/i2c@1c000/tlv320adc3101_34@34";
		tlv320adc3101_36 = "/soc/cbus@ffd00000/i2c@1c000/tlv320adc3101_36@36";
		tlv320adc3101_00 = "/soc/cbus@ffd00000/i2c@1c000/tlv320adc3101_00@00";
		taos_tsl2540 = "/soc/cbus@ffd00000/i2c@1c000/tsl2540@39";
		spicc0 = "/soc/cbus@ffd00000/spi@13000";
		spicc1 = "/soc/cbus@ffd00000/spi@15000";
		aobus = "/soc/aobus@ff800000";
		aoclkc = "/soc/aobus@ff800000/clock-controller@0";
		pwm_AO_ab = "/soc/aobus@ff800000/pwm@7000";
		pwm_AO_cd = "/soc/aobus@ff800000/pwm@2000";
		i2c_AO = "/soc/aobus@ff800000/i2c@5000";
		tlv320aic32x4 = "/soc/aobus@ff800000/i2c@5000/tlv320aic32x4@18";
		i2c_AO_slave = "/soc/aobus@ff800000/i2c_slave@6000";
		uart_AO = "/soc/aobus@ff800000/serial@3000";
		uart_AO_B = "/soc/aobus@ff800000/serial@4000";
		periphs = "/soc/periphs@ff634400";
		hiubus = "/soc/hiubus@ff63c000";
		clkc = "/soc/hiubus@ff63c000/clock-controller@0";
		clkc_b = "/soc/hiubus@ff63c000/clock-controller@1";
		audiobus = "/soc/audiobus@0xff642000";
		clkaudio = "/soc/audiobus@0xff642000/audio_clocks";
		aml_tdma = "/soc/audiobus@0xff642000/tdma";
		aml_tdmb = "/soc/audiobus@0xff642000/tdmb";
		aml_tdmc = "/soc/audiobus@0xff642000/tdmc";
		aml_i2s2hdmi = "/soc/audiobus@0xff642000/i2s2hdmi";
		aml_spdif_a = "/soc/audiobus@0xff642000/spdif_a";
		aml_spdif_b = "/soc/audiobus@0xff642000/spdif_b";
		aml_loopback = "/soc/audiobus@0xff642000/loopback";
		audioresample = "/soc/audiobus@0xff642000/resample";
		aml_pwrdet = "/soc/audiobus@0xff642000/pwrdet";
		remote = "/rc@0xff808040";
		custom_maps = "/custom_maps";
		uart_A = "/serial@ffd24000";
		uart_B = "/serial@ffd23000";
		uart_C = "/serial@ffd22000";
		pcie_A = "/pcieA@fc000000";
		amhdmitx = "/amhdmitx";
		vend_data = "/amhdmitx/vend_data";
		aocec = "/aocec";
		vdin0 = "/vdin0";
		vdin1 = "/vdin1";
		canvas = "/canvas";
		codec_io = "/codec_io";
		gdc = "/gdc";
		meson_fb = "/meson-fb";
		irblaster = "/meson-irblaster";
		sd_emmc_c = "/emmc@ffe07000";
		sd_emmc_b = "/sd@ffe05000";
		sd_emmc_a = "/sdio@ffe03000";
		nand = "/nfc@0";
		bootloader = "/nfc@0/bootloader";
		nandnormal = "/nfc@0/nandnormal";
		nand_partitions = "/nfc@0/nand_partition";
		meson_cooldev = "/meson-cooldev@0";
		cpufreq_cool0 = "/meson-cooldev@0/cpufreq_cool0";
		cpufreq_cool1 = "/meson-cooldev@0/cpufreq_cool1";
		cpucore_cool0 = "/meson-cooldev@0/cpucore_cool0";
		cpucore_cool1 = "/meson-cooldev@0/cpucore_cool1";
		gpufreq_cool0 = "/meson-cooldev@0/gpufreq_cool0";
		gpucore_cool0 = "/meson-cooldev@0/gpucore_cool0";
		vddcpu0 = "/pwmao_d-regulator";
		vddcpu1 = "/pwmab_a-regulator";
		isp_sc = "/isp-sc@ff655400";
		isp = "/isp@ff140000";
		adapter = "/isp-adapter@ff650000";
		phycsi = "/phy-csi@ff650000";
		efuse = "/efuse";
		defendkey = "/defendkey";
		soc_thermal = "/thermal-zones/soc_thermal";
		stage0 = "/thermal-zones/soc_thermal/trips/trip-point@0";
		stage1 = "/thermal-zones/soc_thermal/trips/trip-point@1";
		stage2 = "/thermal-zones/soc_thermal/trips/trip-point@2";
		stage3 = "/thermal-zones/soc_thermal/trips/trip-point@3";
		stage4 = "/thermal-zones/soc_thermal/trips/trip-point@4";
		ddr_thermal = "/thermal-zones/ddr_thermal";
		dswitch_on = "/thermal-zones/ddr_thermal/trips/trip-point@0";
		dcontrol = "/thermal-zones/ddr_thermal/trips/trip-point@1";
		dhot = "/thermal-zones/ddr_thermal/trips/trip-point@2";
		dcritical = "/thermal-zones/ddr_thermal/trips/trip-point@3";
		board_trip10 = "/thermal-zones/board_thermal1/trips/trip-point@0";
		board_trip11 = "/thermal-zones/board_thermal1/trips/trip-point@1";
		board_trip12 = "/thermal-zones/board_thermal1/trips/trip-point@2";
		board_trip13 = "/thermal-zones/board_thermal1/trips/trip-point@3";
		board_trip_critical1 = "/thermal-zones/board_thermal1/trips/trip-point@4";
		board_trip20 = "/thermal-zones/board_thermal2/trips/trip-point@0";
		board_trip21 = "/thermal-zones/board_thermal2/trips/trip-point@1";
		board_trip22 = "/thermal-zones/board_thermal2/trips/trip-point@2";
		board_trip23 = "/thermal-zones/board_thermal2/trips/trip-point@3";
		board_trip_critical2 = "/thermal-zones/board_thermal2/trips/trip-point@4";
		wifi_trip0 = "/thermal-zones/wifi_thermal/trips/trip-point@0";
		wifi_trip1 = "/thermal-zones/wifi_thermal/trips/trip-point@1";
		secmon_reserved = "/reserved-memory/linux,secmon";
		secos_reserved = "/reserved-memory/linux,secos";
		logo_reserved = "/reserved-memory/linux,meson-fb";
		ion_cma_reserved = "/reserved-memory/linux,ion-dev";
		di_cma_reserved = "/reserved-memory/linux,di_cma";
		codec_mm_cma = "/reserved-memory/linux,codec_mm_cma";
		codec_mm_reserved = "/reserved-memory/linux,codec_mm_reserved";
		vdin1_cma_reserved = "/reserved-memory/linux,vdin1_cma";
		wifi_pwm_conf = "/wifi_pwm_conf";
		keysn_0 = "/unifykey/key_0";
		keysn_1 = "/unifykey/key_1";
		keysn_2 = "/unifykey/key_2";
		keysn_3 = "/unifykey/key_3";
		keysn_4 = "/unifykey/key_4";
		keysn_5 = "/unifykey/key_5";
		keysn_6 = "/unifykey/key_6";
		keysn_7 = "/unifykey/key_7";
		keysn_8 = "/unifykey/key_8";
		keysn_9 = "/unifykey/key_9";
		keysn_10 = "/unifykey/key_10";
		keysn_11 = "/unifykey/key_11";
		keysn_12 = "/unifykey/key_12";
		keysn_13 = "/unifykey/key_13";
		keysn_14 = "/unifykey/key_14";
		efusekey = "/efusekey";
		key_0 = "/efusekey/key_0";
		key_1 = "/efusekey/key_1";
		key_2 = "/efusekey/key_2";
		key_3 = "/efusekey/key_3";
		dummy_codec = "/dummy";
		audio_effect = "/eqdrc";
		tdmacpu = "/auge_sound/aml-audio-card,dai-link@0/cpu";
		tdmacodec = "/auge_sound/aml-audio-card,dai-link@0/codec";
		tdmbcodec = "/auge_sound/aml-audio-card,dai-link@1/codec";
		tdmccodec = "/auge_sound/aml-audio-card,dai-link@2/codec";
		cpu_opp_table0 = "/cpu_opp_table0";
		cpu_opp_table1 = "/cpu_opp_table1";
		thermistor0 = "/thermistor0";
		thermistor1 = "/thermistor1";
		thermistor2 = "/thermistor2";
		wifi_sensor = "/wifi-sensor";
		virtual_sensor = "/virtual-sensor";
		wifi_cool = "/virtual-sensor/wifi_cool";
		virtual_sensor2 = "/virtual-sensor2";
	};
};
